[part 1 of 2: package /SwComponentType]
AUTOSAR XML (schema 4-2-2)
package /SwComponentType
  composition sw component type TopLevelComposition
    8 x port group, all with category=PARTIAL_NETWORKING:
      Diagnostics: inner-group=SRS3.Diagnostics
      VehicleDriving: inner-group=SRS3.VehicleDriving
      VehicleModeManagement: inner-group=SRS3.VehicleModeManagement
      SettingsVehicle: inner-group=SRS3.SettingsVehicle
      GlobalShortDuration: inner-group=SRS3.GlobalShortDuration
      Crash: inner-group=SRS3.Crash
      ParkingDrivingClimatization: inner-group=SRS3.ParkingDrivingClimatization
      SeatComfortFunctions: inner-group=SRS3.SeatComfortFunctions
    component SRS3: type=SRS3
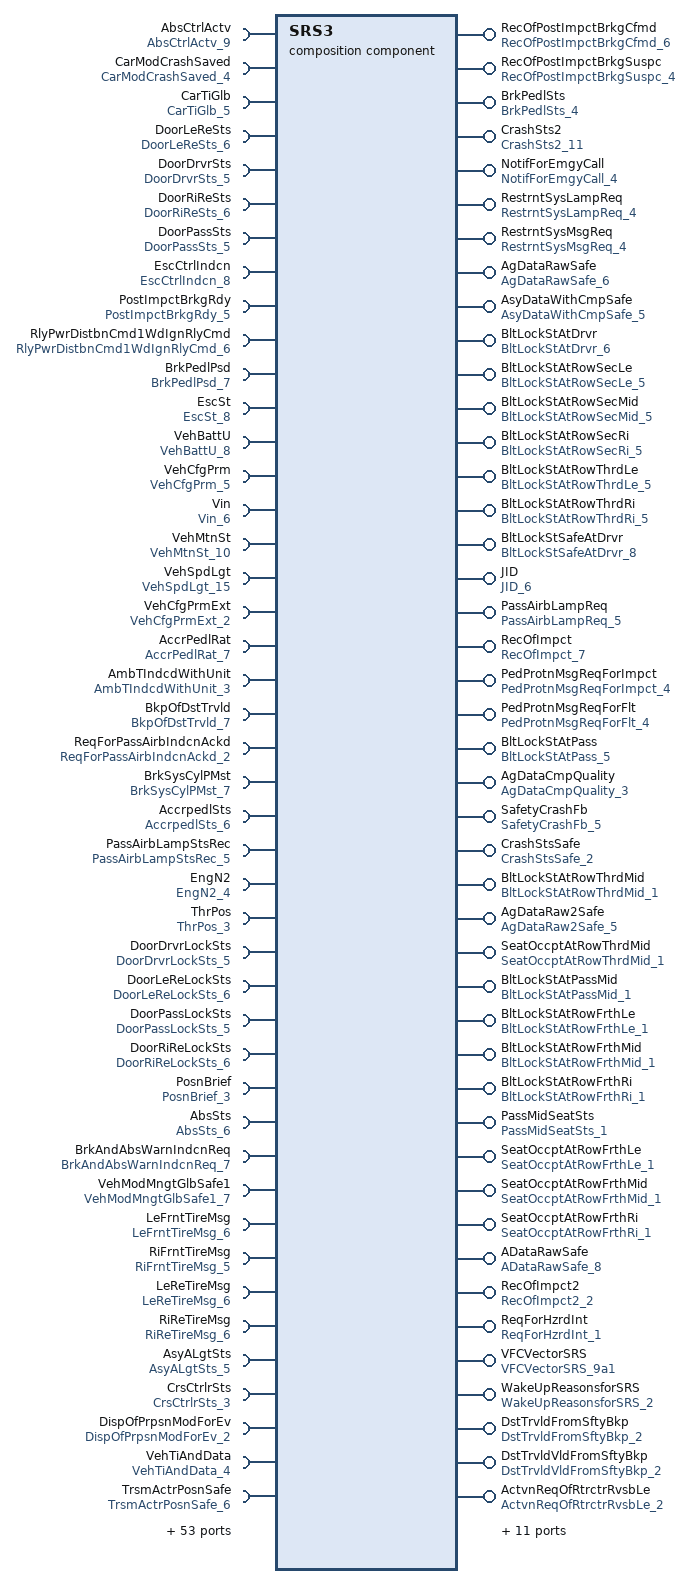
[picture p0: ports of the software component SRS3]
  composition sw component type SRS3
    55 x provide port:
      RecOfPostImpctBrkgCfmd: nonqueued-sender-com-spec{composite-network-representations=[{leaf-element=RecOfPostImpctBrkgCfmd.PostImpctBrkgCfmd, network-representation={base-type=PostImpctBrkgNoYes_2, compu-method=PostImpctBrkgNoYes_1, "ASIL-B(D) signal to inform that a crash has occurred."}}, {leaf-element=RecOfPostImpctBrkgCfmd.CrashFrnt, network-representation={base-type=PostImpctBrkgNoYes_2, compu-method=PostImpctBrkgNoYes_1, "Crash type = front."}}, {leaf-element=RecOfPostImpctBrkgCfmd.CrashSideLe, network-representation={base-type=PostImpctBrkgNoYes_2, compu-method=PostImpctBrkgNoYes_1, "Crash type = left side."}}, {leaf-element=RecOfPostImpctBrkgCfmd.CrashSideRi, network-representation={base-type=PostImpctBrkgNoYes_2, compu-method=PostImpctBrkgNoYes_1, "Crash type = right side."}}, {leaf-element=RecOfPostImpctBrkgCfmd.CrashRe, network-representation={base-type=PostImpctBrkgNoYes_2, compu-method=PostImpctBrkgNoYes_1, "Crash type = rear"}}, {leaf-element=RecOfPostImpctBrkgCfmd.CrashRollovr, network-representation={base-type=PostImpctBrkgNoYes_2, compu-method=PostImpctBrkgNoYes_1, "Crash type = rollover"}}, {leaf-element=RecOfPostImpctBrkgCfmd.CrashPed, network-representation={base-type=PostImpctBrkgNoYes_2, compu-method=PostImpctBrkgNoYes_1, "Crash type = pedestrian impact"}}, {leaf-element=RecOfPostImpctBrkgCfmd.CrashOz, network-representation={base-type=PostImpctBrkgNoYes_2, compu-method=PostImpctBrkgNoYes_1, "Crash type = side offzone (i.e. behind C-pillar or in front of A-pillar.)"}}, {leaf-element=RecOfPostImpctBrkgCfmd.CrashOffroadD, network-representation={base-type=PostImpctBrkgNoYes_2, compu-method=PostImpctBrkgNoYes_1, "Ditch"}}, {leaf-element=RecOfPostImpctBrkgCfmd.CrashOffroadA, network-representation={base-type=PostImpctBrkgNoYes_2, compu-method=PostImpctBrkgNoYes_1, "Airbourne"}}, {leaf-element=RecOfPostImpctBrkgCfmd.CrashOffroadRT, network-representation={base-type=PostImpctBrkgNoYes_2, compu-method=PostImpctBrkgNoYes_1, "Rough Terrain"}}, {leaf-element=RecOfPostImpctBrkgCfmd.CrashOffroadRTsevere, network-representation={base-type=PostImpctBrkgNoYes_2, compu-method=PostImpctBrkgNoYes_1, "Rough Terrain, severe"}}, {leaf-element=RecOfPostImpctBrkgCfmd.CrashLargeAnimal, network-representation={base-type=PostImpctBrkgNoYes_2, compu-method=PostImpctBrkgNoYes_1, "Large Animal"}}, {leaf-element=RecOfPostImpctBrkgCfmd.Chks, network-representation={base-type=UInt8_2, compu {identical; unit Unitless}, "E2E checksum"}}, {leaf-element=RecOfPostImpctBrkgCfmd.Cntr, network-representation={base-type=UInt4_2, compu {identical; unit Unitless}, "E2E counter"}}], data-element=RecOfPostImpctBrkgCfmd, uses-end-to-end-protection=true, init-value=constant-reference=RecOfPostImpctBrkgCfmd_6}, provided-interface=RecOfPostImpctBrkgCfmd_6
      RecOfPostImpctBrkgSuspc: nonqueued-sender-com-spec{composite-network-representations=[{leaf-element=RecOfPostImpctBrkgSuspc.SuspcPostImpctBrkg, network-representation={base-type=PostImpctBrkgNoYes_2, compu-method=PostImpctBrkgNoYes_1, "ASIL-B(D) signal to inform that a crash has occurred."}}, {leaf-element=RecOfPostImpctBrkgSuspc.Chks, network-representation={base-type=UInt8_2, compu {identical; unit Unitless}, "Signal checksum"}}, {leaf-element=RecOfPostImpctBrkgSuspc.Cntr, network-representation={base-type=UInt4_2, compu {identical; unit Unitless}, "Signal counter"}}], data-element=RecOfPostImpctBrkgSuspc, uses-end-to-end-protection=true, init-value=constant-reference=RecOfPostImpctBrkgSuspc_4}, provided-interface=RecOfPostImpctBrkgSuspc_4
      BrkPedlSts: nonqueued-sender-com-spec{data-element=BrkPedlSts, network-representation={base-type=OkNotOk1_2, compu {0=OkNotOk1_Ok, 1=OkNotOk1_NotOk; unit Unitless}, "If the brake pedal decoupling has been activated."}, init-value=constant-reference=BrkPedlSts_4}, provided-interface=BrkPedlSts_4
      CrashSts2: nonqueued-sender-com-spec{data-element=CrashSts2, network-representation={base-type=CrashSts4_1, compu-method=CrashSts4_1, "Information if a crash or slight crash has been detected by SRS."}, init-value=constant-reference=CrashSts2_11}, provided-interface=CrashSts2_11
      NotifForEmgyCall: nonqueued-sender-com-spec{data-element=NotifForEmgyCall, network-representation={base-type=Boolean_2, compu {0=Boolean_FALSE, 1=Boolean_TRUE; unit Unitless}, "Information if there is a need for the vehicle to perform an emergency call."}, init-value=constant-reference=NotifForEmgyCall_4}, provided-interface=NotifForEmgyCall_4
      RestrntSysLampReq: nonqueued-sender-com-spec{data-element=RestrntSysLampReq, network-representation={base-type=RestrntSysLampReq_2, compu-method=RestrntSysLampReq_1, "Indication request for SRS faults."}, init-value=constant-reference=RestrntSysLampReq_4}, provided-interface=RestrntSysLampReq_4
      RestrntSysMsgReq: nonqueued-sender-com-spec{data-element=RestrntSysMsgReq, network-representation={base-type=OnOffCrit1_2, compu-method=OnOffCrit1_1, "Text message request for SRS faults."}, init-value=constant-reference=RestrntSysMsgReq_4}, provided-interface=RestrntSysMsgReq_4
      AgDataRawSafe: nonqueued-sender-com-spec{composite-network-representations=[{leaf-element=AgDataRawSafe.RollRate, network-representation={base-type=AgSpd34_2, compu {phys=raw/4096 for raw -24576..24576; unit rad/s}, "IMU angular rate data. Roll Rate"}}, {leaf-element=AgDataRawSafe.RollRateQf, network-representation={base-type=Qf1_2, compu-method=Qf1_1, "IMU angular rate data. Quality factor for Roll Rate"}}, {leaf-element=AgDataRawSafe.YawRate, network-representation={base-type=AgSpd34_2, compu {phys=raw/4096 for raw -24576..24576; unit rad/s}, "IMU angular rate data. Yaw Rate"}}, {leaf-element=AgDataRawSafe.YawRateQf, network-representation={base-type=Qf1_2, compu-method=Qf1_1, "IMU angular rate data. Quality Factor for Yaw Rate"}}, {leaf-element=AgDataRawSafe.Chks, network-representation={base-type=UInt8_2, compu {identical; unit Unitless}, "IMU angular rate data. Check summa"}}, {leaf-element=AgDataRawSafe.Cntr, network-representation={base-type=UInt4_2, compu {identical; unit Unitless}, "IMU angular rate data. Counter"}}], data-element=AgDataRawSafe, uses-end-to-end-protection=true, init-value=constant-reference=AgDataRawSafe_6}, provided-interface=AgDataRawSafe_6
      AsyDataWithCmpSafe: nonqueued-sender-com-spec{composite-network-representations=[{leaf-element=AsyDataWithCmpSafe.YawRateWithCmp, network-representation={base-type=AgSpd34_2, compu {phys=raw/4096 for raw -24576..24576; unit rad/s}, "IMU processed special data. Compensated Yaw rate"}}, {leaf-element=AsyDataWithCmpSafe.YawRateQf, network-representation={base-type=Qf1_2, compu-method=Qf1_1, "IMU processed special data. Quality Factor for Yaw Rate"}}, {leaf-element=AsyDataWithCmpSafe.ALatWithCmp, network-representation={base-type=A38_2, compu {phys=raw*0.0085 for raw -16352..16353; unit m/s^2}, "IMU processed special data. Compensated Lateral acceleration"}}, {leaf-element=AsyDataWithCmpSafe.ALat1Qf, network-representation={base-type=Qf1_2, compu-method=Qf1_1, "IMU processed special data. Quality factor for Lateral acceleration signal"}}, {leaf-element=AsyDataWithCmpSafe.GrdtOfALgt, network-representation={base-type=Jerk1_2, compu {phys=raw/256 for raw -7680..7680; unit m/s^3}, "IMU processed special data. Derivative of Longitudinal acceleration"}}, {leaf-element=AsyDataWithCmpSafe.ALgt1Qf, network-representation={base-type=Qf1_2, compu-method=Qf1_1, "IMU processed special data. Quality factor for Longitudinal acceleration"}}, {leaf-element=AsyDataWithCmpSafe.Chks, network-representation={base-type=UInt8_2, compu {identical; unit Unitless}, "IMU processed special data. Check sum"}}, {leaf-element=AsyDataWithCmpSafe.Cntr, network-representation={base-type=UInt4_2, compu {identical; unit Unitless}, "IMU processed special data. Counter"}}], data-element=AsyDataWithCmpSafe, uses-end-to-end-protection=true, init-value=constant-reference=AsyDataWithCmpSafe_5}, provided-interface=AsyDataWithCmpSafe_5
      BltLockStAtDrvr: nonqueued-sender-com-spec{composite-network-representations=[{leaf-element=BltLockStAtDrvr.BltLockSt1, network-representation={base-type=BltLockSt1_2, compu {0=BltLockSt1_Unlock, 1=BltLockSt1_Lock; unit Unitless}, "State of belt lock at driver seating position Belt lock state, locked/unlocked"}}, {leaf-element=BltLockStAtDrvr.BltLockSts, network-representation={base-type=DevErrSts2_2, compu {0=DevErrSts2_NoFlt, 1=DevErrSts2_Flt; unit Unitless}, "State of belt lock at driver seating position Belt lock status, OK/NOK"}}], data-element=BltLockStAtDrvr, init-value=constant-reference=BltLockStAtDrvr_6}, provided-interface=BltLockStAtDrvr_6
      BltLockStAtRowSecLe: nonqueued-sender-com-spec{composite-network-representations=[{leaf-element=BltLockStAtRowSecLe.BltLockSt1, network-representation={base-type=BltLockSt1_2, compu {0=BltLockSt1_Unlock, 1=BltLockSt1_Lock; unit Unitless}, "State of belt lock at seating position at left of second row Belt lock state, locked/unlocked"}}, {leaf-element=BltLockStAtRowSecLe.BltLockSts, network-representation={base-type=DevErrSts2_2, compu {0=DevErrSts2_NoFlt, 1=DevErrSts2_Flt; unit Unitless}, "State of belt lock at seating position at left of second row Belt lock status, OK/NOK"}}, {leaf-element=BltLockStAtRowSecLe.BltLockEquid, network-representation={base-type=CptEquid_2, compu {0=CptEquid_Equid, 1=CptEquid_NotEquid; unit Unitless}, "State of belt lock at seating position at left of second row If the belt lock is equipped"}}], data-element=BltLockStAtRowSecLe, init-value=constant-reference=BltLockStAtRowSecLe_5}, provided-interface=BltLockStAtRowSecLe_5
      BltLockStAtRowSecMid: nonqueued-sender-com-spec{composite-network-representations=[{leaf-element=BltLockStAtRowSecMid.BltLockSt1, network-representation={base-type=BltLockSt1_2, compu {0=BltLockSt1_Unlock, 1=BltLockSt1_Lock; unit Unitless}, "State of belt lock at seating position at middle of second row Belt lock state, locked/unlocked"}}, {leaf-element=BltLockStAtRowSecMid.BltLockSts, network-representation={base-type=DevErrSts2_2, compu {0=DevErrSts2_NoFlt, 1=DevErrSts2_Flt; unit Unitless}, "State of belt lock at seating position at middle of second row Belt lock status, OK/NOK"}}, {leaf-element=BltLockStAtRowSecMid.BltLockEquid, network-representation={base-type=CptEquid_2, compu {0=CptEquid_Equid, 1=CptEquid_NotEquid; unit Unitless}, "State of belt lock at seating position at middle of second row If the belt lock is equipped"}}], data-element=BltLockStAtRowSecMid, init-value=constant-reference=BltLockStAtRowSecMid_5}, provided-interface=BltLockStAtRowSecMid_5
      BltLockStAtRowSecRi: nonqueued-sender-com-spec{composite-network-representations=[{leaf-element=BltLockStAtRowSecRi.BltLockSt1, network-representation={base-type=BltLockSt1_2, compu {0=BltLockSt1_Unlock, 1=BltLockSt1_Lock; unit Unitless}, "State of belt lock at seating position at right of second row Belt lock state, locked/unlocked"}}, {leaf-element=BltLockStAtRowSecRi.BltLockSts, network-representation={base-type=DevErrSts2_2, compu {0=DevErrSts2_NoFlt, 1=DevErrSts2_Flt; unit Unitless}, "State of belt lock at seating position at right of second row Belt lock status, OK/NOK"}}, {leaf-element=BltLockStAtRowSecRi.BltLockEquid, network-representation={base-type=CptEquid_2, compu {0=CptEquid_Equid, 1=CptEquid_NotEquid; unit Unitless}, "State of belt lock at seating position at right of second row If the belt lock is equipped"}}], data-element=BltLockStAtRowSecRi, init-value=constant-reference=BltLockStAtRowSecRi_5}, provided-interface=BltLockStAtRowSecRi_5
      BltLockStAtRowThrdLe: nonqueued-sender-com-spec{composite-network-representations=[{leaf-element=BltLockStAtRowThrdLe.BltLockSt1, network-representation={base-type=BltLockSt1_2, compu {0=BltLockSt1_Unlock, 1=BltLockSt1_Lock; unit Unitless}, "State of belt lock at seating position at left of third row Belt lock state, locked/unlocked"}}, {leaf-element=BltLockStAtRowThrdLe.BltLockSts, network-representation={base-type=DevErrSts2_2, compu {0=DevErrSts2_NoFlt, 1=DevErrSts2_Flt; unit Unitless}, "State of belt lock at seating position at left of third row Belt lock status, OK/NOK"}}, {leaf-element=BltLockStAtRowThrdLe.BltLockEquid, network-representation={base-type=CptEquid_2, compu {0=CptEquid_Equid, 1=CptEquid_NotEquid; unit Unitless}, "State of belt lock at seating position at left of third row If the belt lock is equipped"}}], data-element=BltLockStAtRowThrdLe, init-value=constant-reference=BltLockStAtRowThrdLe_5}, provided-interface=BltLockStAtRowThrdLe_5
      BltLockStAtRowThrdRi: nonqueued-sender-com-spec{composite-network-representations=[{leaf-element=BltLockStAtRowThrdRi.BltLockSt1, network-representation={base-type=BltLockSt1_2, compu {0=BltLockSt1_Unlock, 1=BltLockSt1_Lock; unit Unitless}, "State of belt lock at seating position at right of third row Belt lock state, locked/unlocked"}}, {leaf-element=BltLockStAtRowThrdRi.BltLockSts, network-representation={base-type=DevErrSts2_2, compu {0=DevErrSts2_NoFlt, 1=DevErrSts2_Flt; unit Unitless}, "State of belt lock at seating position at right of third row Belt lock status, OK/NOK"}}, {leaf-element=BltLockStAtRowThrdRi.BltLockEquid, network-representation={base-type=CptEquid_2, compu {0=CptEquid_Equid, 1=CptEquid_NotEquid; unit Unitless}, "State of belt lock at seating position at right of third row If the belt lock is equipped"}}], data-element=BltLockStAtRowThrdRi, init-value=constant-reference=BltLockStAtRowThrdRi_5}, provided-interface=BltLockStAtRowThrdRi_5
      BltLockStSafeAtDrvr: nonqueued-sender-com-spec{composite-network-representations=[{leaf-element=BltLockStSafeAtDrvr.BltLockSt1, network-representation={base-type=BltLockSt1_2, compu {0=BltLockSt1_Unlock, 1=BltLockSt1_Lock; unit Unitless}, "State of belt lock at driver seating position Belt lock state, locked/unlocked"}}, {leaf-element=BltLockStSafeAtDrvr.BltLockStErrSts, network-representation={base-type=DevErrSts2_2, compu {0=DevErrSts2_NoFlt, 1=DevErrSts2_Flt; unit Unitless}, "State of belt lock at driver seating position Belt lock status, OK/NOK"}}, {leaf-element=BltLockStSafeAtDrvr.Chks, network-representation={base-type=UInt8_2, compu {identical; unit Unitless}, "Counter for E2E"}}, {leaf-element=BltLockStSafeAtDrvr.Cntr, network-representation={base-type=UInt4_2, compu {identical; unit Unitless}, "Checksum for E2E"}}], data-element=BltLockStSafeAtDrvr, uses-end-to-end-protection=true, init-value=constant-reference=BltLockStSafeAtDrvr_8}, provided-interface=BltLockStSafeAtDrvr_8
      JID: nonqueued-sender-com-spec{composite-network-representations=[{leaf-element=JID.Byte0, network-representation={base-type=UInt8_2, compu {identical; unit Unitless}, "IMU identification number. Byte0"}}, {leaf-element=JID.Byte1, network-representation={base-type=UInt8_2, compu {identical; unit Unitless}, "IMU identification number. Byte1"}}, {leaf-element=JID.Byte2, network-representation={base-type=UInt8_2, compu {identical; unit Unitless}, "IMU identification number. Byte2"}}, {leaf-element=JID.Byte3, network-representation={base-type=UInt8_2, compu {identical; unit Unitless}, "IMU identification number. Byte3"}}, {leaf-element=JID.Byte4, network-representation={base-type=UInt8_2, compu {identical; unit Unitless}, "IMU identification number. Byte4"}}, {leaf-element=JID.Byte5, network-representation={base-type=UInt8_2, compu {identical; unit Unitless}, "IMU identification number. Byte5"}}, {leaf-element=JID.Byte6, network-representation={base-type=UInt8_2, compu {identical; unit Unitless}, "IMU identification number. Byte6"}}, {leaf-element=JID.Byte7, network-representation={base-type=UInt8_2, compu {identical; unit Unitless}, "IMU identification number. Byte7"}}], data-element=JID, init-value=constant-reference=JID_6}, provided-interface=JID_6
      PassAirbLampReq: nonqueued-sender-com-spec{composite-network-representations=[{leaf-element=PassAirbLampReq.PassAirbLampDiReq, network-representation={base-type=PassAirbLampReq_2, compu-method=PassAirbLampReq_1, "Indication request for passenger airbag lamp status. Requested status for PAD lamp"}}, {leaf-element=PassAirbLampReq.PassAirbLampEnaReq, network-representation={base-type=PassAirbLampReq_2, compu-method=PassAirbLampReq_1, "Indication request for passenger airbag lamp status. Requested status for PAE Lamp"}}, {leaf-element=PassAirbLampReq.PassAirbLampReqChks, network-representation={base-type=UInt8_2, compu {identical; unit Unitless}, "Indication request for passenger airbag lamp status. Checksum for validity check of PAD and PAE request messages"}}, {leaf-element=PassAirbLampReq.PassAirbLampReqCntr, network-representation={base-type=UInt4_2, compu {identical; unit Unitless}, "Indication request for passenger airbag lamp status. Counter for validity check of PAD and PAE request messages"}}, {leaf-element=PassAirbLampReq.ChgOfPassAirbSts, network-representation={base-type=ReqForDisp_2, compu {0=ReqForDisp_Idle, 1=ReqForDisp_IndcnReqd; unit Unitless}, "Indication request for passenger airbag lamp status. Reqest for indication of passenger airbag status in DIM"}}], data-element=PassAirbLampReq, uses-end-to-end-protection=true, init-value=constant-reference=PassAirbLampReq_5}, provided-interface=PassAirbLampReq_5
      RecOfImpct: nonqueued-sender-com-spec{composite-network-representations=[{leaf-element=RecOfImpct.VehOri, network-representation={base-type=Orntn_2, compu-method=Orntn_1, "Crash information, Vehicle orientation once crash subsides"}}, {leaf-element=RecOfImpct.CrashState, network-representation={base-type=CrashSt_2, compu-method=CrashSt_1, "Crash information, State of the crash"}}, {leaf-element=RecOfImpct.CrashFrnt, network-representation={base-type=Boolean_2, compu {0=Boolean_FALSE, 1=Boolean_TRUE; unit Unitless}, "Crash information, if crash is frontal"}}, {leaf-element=RecOfImpct.CrashSideLe, network-representation={base-type=Boolean_2, compu {0=Boolean_FALSE, 1=Boolean_TRUE; unit Unitless}, "Crash information, if crash is left side"}}, {leaf-element=RecOfImpct.CrashSideRi, network-representation={base-type=Boolean_2, compu {0=Boolean_FALSE, 1=Boolean_TRUE; unit Unitless}, "Crash information, if crash is right side"}}, {leaf-element=RecOfImpct.CrashRe, network-representation={base-type=Boolean_2, compu {0=Boolean_FALSE, 1=Boolean_TRUE; unit Unitless}, "Crash information, if crash is rear"}}, {leaf-element=RecOfImpct.CrashRollovr, network-representation={base-type=Boolean_2, compu {0=Boolean_FALSE, 1=Boolean_TRUE; unit Unitless}, "Crash information, if crash is roll-over"}}, {leaf-element=RecOfImpct.CrashPed, network-representation={base-type=Boolean_2, compu {0=Boolean_FALSE, 1=Boolean_TRUE; unit Unitless}, "Incident information, if a pedestrian protection triggering has been made"}}, {leaf-element=RecOfImpct.CrashOffroadD, network-representation={base-type=Boolean_2, compu {0=Boolean_FALSE, 1=Boolean_TRUE; unit Unitless}, "Inicdent information, if driving into a ditch has been detected"}}, {leaf-element=RecOfImpct.CrashOffroadA, network-representation={base-type=Boolean_2, compu {0=Boolean_FALSE, 1=Boolean_TRUE; unit Unitless}, "Incident information, if driving off road and becoming airbourne has been detected."}}, {leaf-element=RecOfImpct.CrashOffroadRT, network-representation={base-type=Boolean_2, compu {0=Boolean_FALSE, 1=Boolean_TRUE; unit Unitless}, "Incident information, if driving off the road and into rough terrain has been detected."}}, {leaf-element=RecOfImpct.CrashOffroadRTsevere, network-representation={base-type=Boolean_2, compu {0=Boolean_FALSE, 1=Boolean_TRUE; unit Unitless}, "Incident information, if driving off road and into severe rough terrain has been detected."}}, {leaf-element=RecOfImpct.ImpctDvy, network-representation={base-type=U8Kmph_1, compu {identical; unit Km/h}, "Crash information, change in velocity in y-direction"}}, {leaf-element=RecOfImpct.ImpctDvx, network-representation={base-type=U8Kmph_1, compu {identical; unit Km/h}, "Crash information, change in velocity in x-direction"}}, {leaf-element=RecOfImpct.ImpctRollAg, network-representation={base-type=U8WithRngDeg_1, compu {phys=raw*15 for raw 0..127; unit Deg}, "Crash information, cumulative roll angle"}}], data-element=RecOfImpct, init-value=constant-reference=RecOfImpct_7}, provided-interface=RecOfImpct_7
      PedProtnMsgReqForImpct: nonqueued-sender-com-spec{data-element=PedProtnMsgReqForImpct, network-representation={base-type=OnOff1_2, compu {0=OnOff1_Off, 1=OnOff1_On; unit Unitless}, "Text message request to inform about triggering of the pedestrian protection system."}, init-value=constant-reference=PedProtnMsgReqForImpct_4}, provided-interface=PedProtnMsgReqForImpct_4
      PedProtnMsgReqForFlt: nonqueued-sender-com-spec{data-element=PedProtnMsgReqForFlt, network-representation={base-type=OnOffCrit1_2, compu-method=OnOffCrit1_1, "Indication request for pedestrian protection faults."}, init-value=constant-reference=PedProtnMsgReqForFlt_4}, provided-interface=PedProtnMsgReqForFlt_4
      BltLockStAtPass: nonqueued-sender-com-spec{composite-network-representations=[{leaf-element=BltLockStAtPass.BltLockSt1, network-representation={base-type=BltLockSt1_2, compu {0=BltLockSt1_Unlock, 1=BltLockSt1_Lock; unit Unitless}, "State of belt lock at passenger seating position Belt lock state, locked/unlocked"}}, {leaf-element=BltLockStAtPass.BltLockSts, network-representation={base-type=DevErrSts2_2, compu {0=DevErrSts2_NoFlt, 1=DevErrSts2_Flt; unit Unitless}, "State of belt lock at passenger seating position Belt lock status, OK/NOK"}}], data-element=BltLockStAtPass, init-value=constant-reference=BltLockStAtPass_5}, provided-interface=BltLockStAtPass_5
      AgDataCmpQuality: nonqueued-sender-com-spec{composite-network-representations=[{leaf-element=AgDataCmpQuality.YawRateCmpQuality, network-representation={base-type=UInt8_2, compu {identical; unit Unitless}, "Quality of offset compensation for yawrate"}}, {leaf-element=AgDataCmpQuality.RollRateCmpQuality, network-representation={base-type=UInt8_2, compu {identical; unit Unitless}, "Quality of offset compensation for rollrate"}}, {leaf-element=AgDataCmpQuality.PitchRateCmpQuality, network-representation={base-type=UInt8_2, compu {identical; unit Unitless}, "Quality of offset compensation for pitchrate"}}], data-element=AgDataCmpQuality, init-value=constant-reference=AgDataCmpQuality_3}, provided-interface=AgDataCmpQuality_3
      SafetyCrashFb: nonqueued-sender-com-spec{data-element=SafetyCrashFb, network-representation={base-type=CrashFb_2, compu-method=CrashFb_1, "If brake pedal has been disconnected after a crash it is NOK, else OK after crash."}, init-value=constant-reference=SafetyCrashFb_5}, provided-interface=SafetyCrashFb_5
      CrashStsSafe: nonqueued-sender-com-spec{composite-network-representations=[{leaf-element=CrashStsSafe.Sts, network-representation={base-type=CrashSts2_2, compu {0=CrashSts2_NoCrash, 1=CrashSts2_Crash; unit Unitless}, "Information if a crash has been detected by SRS."}}, {leaf-element=CrashStsSafe.Chks, network-representation={base-type=UInt8_2, compu {identical; unit Unitless}, "Checksum for E2E"}}, {leaf-element=CrashStsSafe.Cntr, network-representation={base-type=UInt4_2, compu {identical; unit Unitless}, "Counter for E2E"}}], data-element=CrashStsSafe, uses-end-to-end-protection=true, init-value=constant-reference=CrashStsSafe_2}, provided-interface=CrashStsSafe_2
      BltLockStAtRowThrdMid: nonqueued-sender-com-spec{composite-network-representations=[{leaf-element=BltLockStAtRowThrdMid.BltLockSt1, network-representation={base-type=BltLockSt1_2, compu {0=BltLockSt1_Unlock, 1=BltLockSt1_Lock; unit Unitless}, "State of belt lock at seating position at middle third row Belt lock state, locked/unlocked"}}, {leaf-element=BltLockStAtRowThrdMid.BltLockSts, network-representation={base-type=DevErrSts2_2, compu {0=DevErrSts2_NoFlt, 1=DevErrSts2_Flt; unit Unitless}, "State of belt lock at seating position at middle third row Belt lock status, OK/NOK"}}, {leaf-element=BltLockStAtRowThrdMid.BltLockEquid, network-representation={base-type=CptEquid_2, compu {0=CptEquid_Equid, 1=CptEquid_NotEquid; unit Unitless}, "State of belt lock at seating position at middle third row If the belt lock is equipped"}}], data-element=BltLockStAtRowThrdMid, init-value=constant-reference=BltLockStAtRowThrdMid_1}, provided-interface=BltLockStAtRowThrdMid_1
      AgDataRaw2Safe: nonqueued-sender-com-spec{composite-network-representations=[{leaf-element=AgDataRaw2Safe.Chks, network-representation={base-type=UInt8_2, compu {identical; unit Unitless}, "IMU pitch rate data. Check sum"}}, {leaf-element=AgDataRaw2Safe.Cntr, network-representation={base-type=UInt4_2, compu {identical; unit Unitless}, "IMU pitch rate data. Counter"}}, {leaf-element=AgDataRaw2Safe.PitchRateQf, network-representation={base-type=Qf1_2, compu-method=Qf1_1, "IMU pitch rate data. Quality factor for Pitch Rate"}}, {leaf-element=AgDataRaw2Safe.PitchRate, network-representation={base-type=AgSpd34_2, compu {phys=raw/4096 for raw -24576..24576; unit rad/s}, "IMU pitch rate data. Pitch Rate"}}], data-element=AgDataRaw2Safe, uses-end-to-end-protection=true, init-value=constant-reference=AgDataRaw2Safe_5}, provided-interface=AgDataRaw2Safe_5
      SeatOccptAtRowThrdMid: nonqueued-sender-com-spec{data-element=SeatOccptAtRowThrdMid, network-representation={base-type=PassSeatSts1_2, compu-method=PassSeatSts1_1, "Occupant presence status at 3rd row , right position."}, init-value=constant-reference=SeatOccptAtRowThrdMid_1}, provided-interface=SeatOccptAtRowThrdMid_1
      BltLockStAtPassMid: nonqueued-sender-com-spec{composite-network-representations=[{leaf-element=BltLockStAtPassMid.BltLockSt1, network-representation={base-type=BltLockSt1_2, compu {0=BltLockSt1_Unlock, 1=BltLockSt1_Lock; unit Unitless}, "Belt lock state at 1st row middle passenger seat position. Signal gives out if the belt lock is locked or unlocked."}}, {leaf-element=BltLockStAtPassMid.BltLockSts, network-representation={base-type=DevErrSts2_2, compu {0=DevErrSts2_NoFlt, 1=DevErrSts2_Flt; unit Unitless}, "Belt lock state at 1st row middle passenger seat position. Signal gives out if the belt lock is faulty or not."}}, {leaf-element=BltLockStAtPassMid.BltLockEquid, network-representation={base-type=CptEquid_2, compu {0=CptEquid_Equid, 1=CptEquid_NotEquid; unit Unitless}, "Belt lock state at 1st row middle passenger seat position. Signal gives out if the belt lock sensor is equipped or not."}}], data-element=BltLockStAtPassMid, init-value=constant-reference=BltLockStAtPassMid_1}, provided-interface=BltLockStAtPassMid_1
      BltLockStAtRowFrthLe: nonqueued-sender-com-spec{composite-network-representations=[{leaf-element=BltLockStAtRowFrthLe.BltLockSt1, network-representation={base-type=BltLockSt1_2, compu {0=BltLockSt1_Unlock, 1=BltLockSt1_Lock; unit Unitless}, "Belt lock state at 4th row outer left seat posiiton. Signal gives out if the belt lock is locked or unlocked."}}, {leaf-element=BltLockStAtRowFrthLe.BltLockSts, network-representation={base-type=DevErrSts2_2, compu {0=DevErrSts2_NoFlt, 1=DevErrSts2_Flt; unit Unitless}, "Belt lock fault status at the 4th row outer left seat. Signal gives out if belt lock is faulty or not."}}, {leaf-element=BltLockStAtRowFrthLe.BltLockEquid, network-representation={base-type=CptEquid_2, compu {0=CptEquid_Equid, 1=CptEquid_NotEquid; unit Unitless}, "Signal gives out if belt lock detection sensor is equipped at the 4th row outer left seat."}}], data-element=BltLockStAtRowFrthLe, init-value=constant-reference=BltLockStAtRowFrthLe_1}, provided-interface=BltLockStAtRowFrthLe_1
      BltLockStAtRowFrthMid: nonqueued-sender-com-spec{composite-network-representations=[{leaf-element=BltLockStAtRowFrthMid.BltLockSt1, network-representation={base-type=BltLockSt1_2, compu {0=BltLockSt1_Unlock, 1=BltLockSt1_Lock; unit Unitless}, "Belt lock state at 4th row middle seat posiiton. Signal gives out if the belt lock is locked or unlocked."}}, {leaf-element=BltLockStAtRowFrthMid.BltLockSts, network-representation={base-type=DevErrSts2_2, compu {0=DevErrSts2_NoFlt, 1=DevErrSts2_Flt; unit Unitless}, "Belt lock fault status at the 4th row middle seat. Signal gives out if belt lock is faulty or not."}}, {leaf-element=BltLockStAtRowFrthMid.BltLockEquid, network-representation={base-type=CptEquid_2, compu {0=CptEquid_Equid, 1=CptEquid_NotEquid; unit Unitless}, "Signal gives out if belt lock detection sensor is equipped at the 4th row middle seat."}}], data-element=BltLockStAtRowFrthMid, init-value=constant-reference=BltLockStAtRowFrthMid_1}, provided-interface=BltLockStAtRowFrthMid_1
      BltLockStAtRowFrthRi: nonqueued-sender-com-spec{composite-network-representations=[{leaf-element=BltLockStAtRowFrthRi.BltLockSt1, network-representation={base-type=BltLockSt1_2, compu {0=BltLockSt1_Unlock, 1=BltLockSt1_Lock; unit Unitless}, "Belt lock state at 4th row outer right seat posiiton. Signal gives out if the belt lock is locked or unlocked."}}, {leaf-element=BltLockStAtRowFrthRi.BltLockSts, network-representation={base-type=DevErrSts2_2, compu {0=DevErrSts2_NoFlt, 1=DevErrSts2_Flt; unit Unitless}, "Belt lock fault status at the 4th row outer right seat. Signal gives out if belt lock is faulty or not."}}, {leaf-element=BltLockStAtRowFrthRi.BltLockEquid, network-representation={base-type=CptEquid_2, compu {0=CptEquid_Equid, 1=CptEquid_NotEquid; unit Unitless}, "Signal gives out if belt lock detection sensor is equipped at the 4th row outer right seat."}}], data-element=BltLockStAtRowFrthRi, init-value=constant-reference=BltLockStAtRowFrthRi_1}, provided-interface=BltLockStAtRowFrthRi_1
      PassMidSeatSts: nonqueued-sender-com-spec{data-element=PassMidSeatSts, network-representation={base-type=PassSeatSts1_2, compu-method=PassSeatSts1_1, "Occupation status based on occupant detection sensor at front row middle seat."}, init-value=constant-reference=PassMidSeatSts_1}, provided-interface=PassMidSeatSts_1
      SeatOccptAtRowFrthLe: nonqueued-sender-com-spec{data-element=SeatOccptAtRowFrthLe, network-representation={base-type=PassSeatSts1_2, compu-method=PassSeatSts1_1, "Occupation status based on occupant detection sensor at the 4th row outer left seat."}, init-value=constant-reference=SeatOccptAtRowFrthLe_1}, provided-interface=SeatOccptAtRowFrthLe_1
      SeatOccptAtRowFrthMid: nonqueued-sender-com-spec{data-element=SeatOccptAtRowFrthMid, network-representation={base-type=PassSeatSts1_2, compu-method=PassSeatSts1_1, "Occupation status based on occupant detection sensor at the 4th middle seat."}, init-value=constant-reference=SeatOccptAtRowFrthMid_1}, provided-interface=SeatOccptAtRowFrthMid_1
      SeatOccptAtRowFrthRi: nonqueued-sender-com-spec{data-element=SeatOccptAtRowFrthRi, network-representation={base-type=PassSeatSts1_2, compu-method=PassSeatSts1_1, "Occupation status based on occupant detection sensor at the 4th row outer right seat."}, init-value=constant-reference=SeatOccptAtRowFrthRi_1}, provided-interface=SeatOccptAtRowFrthRi_1
      ADataRawSafe: nonqueued-sender-com-spec{composite-network-representations=[{leaf-element=ADataRawSafe.ALat, network-representation={base-type=A38_2, compu {phys=raw*0.0085 for raw -16352..16353; unit m/s^2}, "IMU acceleration data Lateral acceleration"}}, {leaf-element=ADataRawSafe.ALat1Qf, network-representation={base-type=Qf1_2, compu-method=Qf1_1, "IMU acceleration data Quality factor for Lateral acceleration signal"}}, {leaf-element=ADataRawSafe.ALgt, network-representation={base-type=A38_2, compu {phys=raw*0.0085 for raw -16352..16353; unit m/s^2}, "IMU acceleration data Longitudinal acceleration"}}, {leaf-element=ADataRawSafe.ALgt1Qf, network-representation={base-type=Qf1_2, compu-method=Qf1_1, "IMU acceleration data Quality factor for Longitudinal acceleration"}}, {leaf-element=ADataRawSafe.AVert, network-representation={base-type=A38_2, compu {phys=raw*0.0085 for raw -16352..16353; unit m/s^2}, "IMU acceleration data Vertical acceleration"}}, {leaf-element=ADataRawSafe.AVertQf, network-representation={base-type=Qf1_2, compu-method=Qf1_1, "IMU acceleration data Quality factor for Vertical acceleration"}}, {leaf-element=ADataRawSafe.Chks, network-representation={base-type=UInt8_2, compu {identical; unit Unitless}, "IMU acceleration data Check sum"}}, {leaf-element=ADataRawSafe.Cntr, network-representation={base-type=UInt4_2, compu {identical; unit Unitless}, "IMU acceleration data Counter"}}], data-element=ADataRawSafe, uses-end-to-end-protection=true, init-value=constant-reference=ADataRawSafe_8}, provided-interface=ADataRawSafe_8
      RecOfImpct2: nonqueued-sender-com-spec{composite-network-representations=[{leaf-element=RecOfImpct2.ImpctDvxSigned, network-representation={base-type=Spd51_1, compu {phys=raw-255 for raw 0..512; unit Km/h}, "Crash information , changed velocity in x direction , data with sign"}}, {leaf-element=RecOfImpct2.ImpctDvySigned, network-representation={base-type=Spd51_1, compu {phys=raw-255 for raw 0..512; unit Km/h}, "Crash information , changed velocity in y direction, data with sign"}}], data-element=RecOfImpct2, init-value=constant-reference=RecOfImpct2_2}, provided-interface=RecOfImpct2_2
      ReqForHzrdInt: nonqueued-sender-com-spec{data-element=ReqForHzrdInt, network-representation={base-type=ReqForHzrdInt_1, compu-method=ReqForHzrdInt_1, "0-Lower crash not happen 1-Lower crash happened"}, init-value=constant-reference=ReqForHzrdInt_1}, provided-interface=ReqForHzrdInt_1
      VFCVectorSRS: nonqueued-sender-com-spec{composite-network-representations=[{leaf-element=VFCVectorSRS.VFCid1, network-representation={base-type=VFCOnOff_4, compu {0=VFCOnOff_Off, 1=VFCOnOff_On; unit Unitless}, "ParkingDrivingClimatization"}}, {leaf-element=VFCVectorSRS.VFCid2, network-representation={base-type=VFCOnOff_4, compu {0=VFCOnOff_Off, 1=VFCOnOff_On; unit Unitless}, "PostClimatisation"}}, {leaf-element=VFCVectorSRS.VFCid3, network-representation={base-type=VFCOnOff_4, compu {0=VFCOnOff_Off, 1=VFCOnOff_On; unit Unitless}, "PowertrainParkingClimatization"}}, {leaf-element=VFCVectorSRS.VFCid4, network-representation={base-type=VFCOnOff_4, compu {0=VFCOnOff_Off, 1=VFCOnOff_On; unit Unitless}, "VFC4"}}, {leaf-element=VFCVectorSRS.VFCid5, network-representation={base-type=VFCOnOff_4, compu {0=VFCOnOff_Off, 1=VFCOnOff_On; unit Unitless}, "VFC5"}}, {leaf-element=VFCVectorSRS.VFCid6, network-representation={base-type=VFCOnOff_4, compu {0=VFCOnOff_Off, 1=VFCOnOff_On; unit Unitless}, "SettingsVehicle"}}, {leaf-element=VFCVectorSRS.VFCid7, network-representation={base-type=VFCOnOff_4, compu {0=VFCOnOff_Off, 1=VFCOnOff_On; unit Unitless}, "VFC7"}}, {leaf-element=VFCVectorSRS.VFCid8, network-representation={base-type=VFCOnOff_4, compu {0=VFCOnOff_Off, 1=VFCOnOff_On; unit Unitless}, "VFC8"}}, {leaf-element=VFCVectorSRS.VFCid9, network-representation={base-type=VFCOnOff_4, compu {0=VFCOnOff_Off, 1=VFCOnOff_On; unit Unitless}, "IPWakeup"}}, {leaf-element=VFCVectorSRS.VFCid10, network-representation={base-type=VFCOnOff_4, compu {0=VFCOnOff_Off, 1=VFCOnOff_On; unit Unitless}, "ExteriorLighting"}}, {leaf-element=VFCVectorSRS.VFCid11, network-representation={base-type=VFCOnOff_4, compu {0=VFCOnOff_Off, 1=VFCOnOff_On; unit Unitless}, "VFC11"}}, {leaf-element=VFCVectorSRS.VFCid12, network-representation={base-type=VFCOnOff_4, compu {0=VFCOnOff_Off, 1=VFCOnOff_On; unit Unitless}, "Alarm"}}, {leaf-element=VFCVectorSRS.VFCid13, network-representation={base-type=VFCOnOff_4, compu {0=VFCOnOff_Off, 1=VFCOnOff_On; unit Unitless}, "VFC13"}}, {leaf-element=VFCVectorSRS.VFCid14, network-representation={base-type=VFCOnOff_4, compu {0=VFCOnOff_Off, 1=VFCOnOff_On; unit Unitless}, "InteriorLighting"}}, {leaf-element=VFCVectorSRS.VFCid15, network-representation={base-type=VFCOnOff_4, compu {0=VFCOnOff_Off, 1=VFCOnOff_On; unit Unitless}, "VFC15"}}, {leaf-element=VFCVectorSRS.VFCid16, network-representation={base-type=VFCOnOff_4, compu {0=VFCOnOff_Off, 1=VFCOnOff_On; unit Unitless}, "Locking"}}, {leaf-element=VFCVectorSRS.VFCid17, network-representation={base-type=VFCOnOff_4, compu {0=VFCOnOff_Off, 1=VFCOnOff_On; unit Unitless}, "RemoteKeyFunctionality"}}, {leaf-element=VFCVectorSRS.VFCid18, network-representation={base-type=VFCOnOff_4, compu {0=VFCOnOff_Off, 1=VFCOnOff_On; unit Unitless}, "PropulsionStart"}}, {leaf-element=VFCVectorSRS.VFCid19, network-representation={base-type=VFCOnOff_4, compu {0=VFCOnOff_Off, 1=VFCOnOff_On; unit Unitless}, "VFC19"}}, {leaf-element=VFCVectorSRS.VFCid20, network-representation={base-type=VFCOnOff_4, compu {0=VFCOnOff_Off, 1=VFCOnOff_On; unit Unitless}, "VFC20"}}, {leaf-element=VFCVectorSRS.VFCid21, network-representation={base-type=VFCOnOff_4, compu {0=VFCOnOff_Off, 1=VFCOnOff_On; unit Unitless}, "PowerClosures"}}, {leaf-element=VFCVectorSRS.VFCid22, network-representation={base-type=VFCOnOff_4, compu {0=VFCOnOff_Off, 1=VFCOnOff_On; unit Unitless}, "VehicleDriving"}}, {leaf-element=VFCVectorSRS.VFCid23, network-representation={base-type=VFCOnOff_4, compu {0=VFCOnOff_Off, 1=VFCOnOff_On; unit Unitless}, "VFC23"}}, {leaf-element=VFCVectorSRS.VFCid24, network-representation={base-type=VFCOnOff_4, compu {0=VFCOnOff_Off, 1=VFCOnOff_On; unit Unitless}, "SettingsProfile"}}, {leaf-element=VFCVectorSRS.VFCid25, network-representation={base-type=VFCOnOff_4, compu {0=VFCOnOff_Off, 1=VFCOnOff_On; unit Unitless}, "SeatComfortFunctions"}}, {leaf-element=VFCVectorSRS.VFCid26, network-representation={base-type=VFCOnOff_4, compu {0=VFCOnOff_Off, 1=VFCOnOff_On; unit Unitless}, "Brake"}}, {leaf-element=VFCVectorSRS.VFCid27, network-representation={base-type=VFCOnOff_4, compu {0=VFCOnOff_Off, 1=VFCOnOff_On; unit Unitless}, "InfotainmentPoll"}}, {leaf-element=VFCVectorSRS.VFCid28, network-representation={base-type=VFCOnOff_4, compu {0=VFCOnOff_Off, 1=VFCOnOff_On; unit Unitless}, "HVEnergyStorage"}}, {leaf-element=VFCVectorSRS.VFCid29, network-representation={base-type=VFCOnOff_4, compu {0=VFCOnOff_Off, 1=VFCOnOff_On; unit Unitless}, "VFC29"}}, {leaf-element=VFCVectorSRS.VFCid30, network-representation={base-type=VFCOnOff_4, compu {0=VFCOnOff_Off, 1=VFCOnOff_On; unit Unitless}, "TelematicsConnectivity"}}, {leaf-element=VFCVectorSRS.VFCid31, network-representation={base-type=VFCOnOff_4, compu {0=VFCOnOff_Off, 1=VFCOnOff_On; unit Unitless}, "VFC31"}}, {leaf-element=VFCVectorSRS.VFCid32, network-representation={base-type=VFCOnOff_4, compu {0=VFCOnOff_Off, 1=VFCOnOff_On; unit Unitless}, "VFC32"}}, {leaf-element=VFCVectorSRS.VFCid33, network-representation={base-type=VFCOnOff_4, compu {0=VFCOnOff_Off, 1=VFCOnOff_On; unit Unitless}, "Diagnostics"}}, {leaf-element=VFCVectorSRS.VFCid34, network-representation={base-type=VFCOnOff_4, compu {0=VFCOnOff_Off, 1=VFCOnOff_On; unit Unitless}, "VehicleModeManagement"}}, {leaf-element=VFCVectorSRS.VFCid35, network-representation={base-type=VFCOnOff_4, compu {0=VFCOnOff_Off, 1=VFCOnOff_On; unit Unitless}, "TrailerCaravanFunctions"}}, {leaf-element=VFCVectorSRS.VFCid36, network-representation={base-type=VFCOnOff_4, compu {0=VFCOnOff_Off, 1=VFCOnOff_On; unit Unitless}, "Immobilizer"}}, {leaf-element=VFCVectorSRS.VFCid37, network-representation={base-type=VFCOnOff_4, compu {0=VFCOnOff_Off, 1=VFCOnOff_On; unit Unitless}, "Windows"}}, {leaf-element=VFCVectorSRS.VFCid38, network-representation={base-type=VFCOnOff_4, compu {0=VFCOnOff_Off, 1=VFCOnOff_On; unit Unitless}, "Visibility"}}, {leaf-element=VFCVectorSRS.VFCid39, network-representation={base-type=VFCOnOff_4, compu {0=VFCOnOff_Off, 1=VFCOnOff_On; unit Unitless}, "VFC39"}}, {leaf-element=VFCVectorSRS.VFCid40, network-representation={base-type=VFCOnOff_4, compu {0=VFCOnOff_Off, 1=VFCOnOff_On; unit Unitless}, "VFC40"}}, {leaf-element=VFCVectorSRS.VFCid41, network-representation={base-type=VFCOnOff_4, compu {0=VFCOnOff_Off, 1=VFCOnOff_On; unit Unitless}, "InfotainmentPush"}}, {leaf-element=VFCVectorSRS.VFCid42, network-representation={base-type=VFCOnOff_4, compu {0=VFCOnOff_Off, 1=VFCOnOff_On; unit Unitless}, "ChargingHV"}}, {leaf-element=VFCVectorSRS.VFCid43, network-representation={base-type=VFCOnOff_4, compu {0=VFCOnOff_Off, 1=VFCOnOff_On; unit Unitless}, "BodyPreClimatisation"}}, {leaf-element=VFCVectorSRS.VFCid44, network-representation={base-type=VFCOnOff_4, compu {0=VFCOnOff_Off, 1=VFCOnOff_On; unit Unitless}, "Crash"}}, {leaf-element=VFCVectorSRS.VFCid45, network-representation={base-type=VFCOnOff_4, compu {0=VFCOnOff_Off, 1=VFCOnOff_On; unit Unitless}, "GlobalShortDuration"}}, {leaf-element=VFCVectorSRS.VFCid46, network-representation={base-type=VFCOnOff_4, compu {0=VFCOnOff_Off, 1=VFCOnOff_On; unit Unitless}, "ExteriorLightsHazard"}}, {leaf-element=VFCVectorSRS.VFCid47, network-representation={base-type=VFCOnOff_4, compu {0=VFCOnOff_Off, 1=VFCOnOff_On; unit Unitless}, "VFC47"}}, {leaf-element=VFCVectorSRS.VFCid48, network-representation={base-type=VFCOnOff_4, compu {0=VFCOnOff_Off, 1=VFCOnOff_On; unit Unitless}, "DoorOpenWarning"}}, {leaf-element=VFCVectorSRS.VFCid49, network-representation={base-type=VFCOnOff_4, compu {0=VFCOnOff_Off, 1=VFCOnOff_On; unit Unitless}, "ChargingLVInit"}}, {leaf-element=VFCVectorSRS.VFCid50, network-representation={base-type=VFCOnOff_4, compu {0=VFCOnOff_Off, 1=VFCOnOff_On; unit Unitless}, "VFC50"}}, {leaf-element=VFCVectorSRS.VFCid51, network-representation={base-type=VFCOnOff_4, compu {0=VFCOnOff_Off, 1=VFCOnOff_On; unit Unitless}, "VFC51"}}, {leaf-element=VFCVectorSRS.VFCid52, network-representation={base-type=VFCOnOff_4, compu {0=VFCOnOff_Off, 1=VFCOnOff_On; unit Unitless}, "HVBatteryThermalEventWarning"}}, {leaf-element=VFCVectorSRS.VFCid53, network-representation={base-type=VFCOnOff_4, compu {0=VFCOnOff_Off, 1=VFCOnOff_On; unit Unitless}, "VisualAssist"}}, {leaf-element=VFCVectorSRS.VFCid54, network-representation={base-type=VFCOnOff_4, compu {0=VFCOnOff_Off, 1=VFCOnOff_On; unit Unitless}, "PassiveSafety"}}, {leaf-element=VFCVectorSRS.VFCid55, network-representation={base-type=VFCOnOff_4, compu {0=VFCOnOff_Off, 1=VFCOnOff_On; unit Unitless}, "LifeDetection"}}, {leaf-element=VFCVectorSRS.VFCid56, network-representation={base-type=VFCOnOff_4, compu {0=VFCOnOff_Off, 1=VFCOnOff_On; unit Unitless}, "BackboneFlexray"}}, {leaf-element=VFCVectorSRS.VFCid57, network-representation={base-type=VFCOnOff_4, compu {0=VFCOnOff_Off, 1=VFCOnOff_On; unit Unitless}, "Functionmarket"}}, {leaf-element=VFCVectorSRS.VFCid58, network-representation={base-type=VFCOnOff_4, compu {0=VFCOnOff_Off, 1=VFCOnOff_On; unit Unitless}, "VFC58"}}, {leaf-element=VFCVectorSRS.VFCid59, network-representation={base-type=VFCOnOff_4, compu {0=VFCOnOff_Off, 1=VFCOnOff_On; unit Unitless}, "VFC59"}}, {leaf-element=VFCVectorSRS.VFCid60, network-representation={base-type=VFCOnOff_4, compu {0=VFCOnOff_Off, 1=VFCOnOff_On; unit Unitless}, "VFC60"}}, {leaf-element=VFCVectorSRS.VFCid61, network-representation={base-type=VFCOnOff_4, compu {0=VFCOnOff_Off, 1=VFCOnOff_On; unit Unitless}, "VFC61"}}, {leaf-element=VFCVectorSRS.VFCid0, network-representation={base-type=VFCOnOff_4, compu {0=VFCOnOff_Off, 1=VFCOnOff_On; unit Unitless}, "SettingsComfort"}}, {leaf-element=VFCVectorSRS.BlockID, network-representation={base-type=BlockID_3, compu {identical; unit Unitless}, "BlockID"}}], data-element=VFCVectorSRS, init-value=constant-reference=VFCVectorSRS_9a1}, provided-interface=VFCVectorSRS_9a1
      WakeUpReasonsforSRS: nonqueued-sender-com-spec{data-element=WakeUpReasonsforSRS, network-representation={base-type=WakeUpReasons_4, compu-method=WakeupReasons_7, "WakeUpReasons"}, init-value=constant-reference=WakeUpReasonsforSRS_2}, provided-interface=WakeUpReasonsforSRS_2
      DstTrvldFromSftyBkp: nonqueued-sender-com-spec{data-element=DstTrvldFromSftyBkp, network-representation={base-type=Len31_2, compu {phys=raw for raw 0..2000000; unit km}, "Saved backupvalue"}, init-value=constant-reference=DstTrvldFromSftyBkp_2}, provided-interface=DstTrvldFromSftyBkp_2
      DstTrvldVldFromSftyBkp: nonqueued-sender-com-spec{data-element=DstTrvldVldFromSftyBkp, network-representation={base-type=InvldVld1_2, compu {0=InvldVld1_Invld, 1=InvldVld1_Vld; unit Unitless}, "Indication if the transmitted backupvalue is valid or not"}, init-value=constant-reference=DstTrvldVldFromSftyBkp_2}, provided-interface=DstTrvldVldFromSftyBkp_2
      ActvnReqOfRtrctrRvsbLe: nonqueued-sender-com-spec{data-element=ActvnReqOfRtrctrRvsbLe, network-representation={base-type=ActvnReqOfRtrctrRvsb1_2, compu {0=NoActvn, 1=ActvnFLo, 2=ActvnFHi, 3=Resd1, 4=Resd2; unit Unitless}, "Belt pre-tensioning request from the DART/CWS algo in the SRS."}, init-value=constant-reference=ActvnReqOfRtrctrRvsbLe_2}, provided-interface=ActvnReqOfRtrctrRvsbLe_2
      ActvnReqOfRtrctrRvsbRi: nonqueued-sender-com-spec{data-element=ActvnReqOfRtrctrRvsbRi, network-representation={base-type=ActvnReqOfRtrctrRvsb1_2, compu {0=NoActvn, 1=ActvnFLo, 2=ActvnFHi, 3=Resd1, 4=Resd2; unit Unitless}, "Belt pre-tensioning request from the DART/CWS algo in the SRS."}, init-value=constant-reference=ActvnReqOfRtrctrRvsbRi_2}, provided-interface=ActvnReqOfRtrctrRvsbRi_2
      BltCrashNotif: nonqueued-sender-com-spec{composite-network-representations=[{leaf-element=BltCrashNotif.BltCrashNotifDrvr, network-representation={base-type=NoYesCrit1_2, compu-method=NoYesCrit1_1, "Status signal for driver belt pyrotechnic activation."}}, {leaf-element=BltCrashNotif.BltCrashNotifPass, network-representation={base-type=NoYesCrit1_2, compu-method=NoYesCrit1_1, "Status signal for passenger belt pyrotechnic activation."}}], data-element=BltCrashNotif, init-value=constant-reference=BltCrashNotif_4}, provided-interface=BltCrashNotif_4
      PassAirbSts: nonqueued-sender-com-spec{data-element=PassAirbSts, network-representation={base-type=OnOff2_2, compu {0=OnOff2_On, 1=OnOff2_Off; unit Unitless}, "Passenger airbag status, based on PACOS input."}, init-value=constant-reference=PassAirbSts_5}, provided-interface=PassAirbSts_5
      SRSdevelpsignalgroupTX: nonqueued-sender-com-spec{composite-network-representations=[{leaf-element=SRSdevelpsignalgroupTX.Functiondevpsignalgroup1, network-representation={base-type=UInt8_2, compu {identical; unit Unitless}, "SRS development signal"}}, {leaf-element=SRSdevelpsignalgroupTX.Functiondevpsignalgroup2, network-representation={base-type=UInt8_2, compu {identical; unit Unitless}, "SRS development signal"}}, {leaf-element=SRSdevelpsignalgroupTX.Functiondevpsignalgroup3, network-representation={base-type=UInt8_2, compu {identical; unit Unitless}, "SRS development signal"}}, {leaf-element=SRSdevelpsignalgroupTX.Functiondevpsignalgroup4, network-representation={base-type=UInt8_2, compu {identical; unit Unitless}, "SRS development signal"}}, {leaf-element=SRSdevelpsignalgroupTX.Functiondevpsignalgroup5, network-representation={base-type=UInt8_2, compu {identical; unit Unitless}, "SRS development signal"}}, {leaf-element=SRSdevelpsignalgroupTX.Functiondevpsignalgroup6, network-representation={base-type=UInt8_2, compu {identical; unit Unitless}, "SRS development signal"}}, {leaf-element=SRSdevelpsignalgroupTX.Functiondevpsignalgroup7, network-representation={base-type=UInt8_2, compu {identical; unit Unitless}, "SRS development signal"}}, {leaf-element=SRSdevelpsignalgroupTX.Functiondevpsignalgroup8, network-representation={base-type=UInt8_2, compu {identical; unit Unitless}, "SRS development signal"}}], data-element=SRSdevelpsignalgroupTX, init-value=constant-reference=SRSdevelpsignalgroupTX_3}, provided-interface=SRSdevelpsignalgroupTX_3
      SRSResdSig1ToZCUDMSafety: nonqueued-sender-com-spec{composite-network-representations=[{leaf-element=SRSResdSig1ToZCUDMSafety.Chks, network-representation={base-type=UInt8_2, compu {identical; unit Unitless}, "SRSResdSig1ToZCUDMSafety"}}, {leaf-element=SRSResdSig1ToZCUDMSafety.Cntr, network-representation={base-type=UInt4_2, compu {identical; unit Unitless}, "SRSResdSig1ToZCUDMSafety"}}, {leaf-element=SRSResdSig1ToZCUDMSafety.UInt32, network-representation={base-type=UInt32_2, compu {identical; unit Unitless}, "SRSResdSig1ToZCUDMSafety"}}], data-element=SRSResdSig1ToZCUDMSafety, uses-end-to-end-protection=true, init-value=constant-reference=SRSResdSig1ToZCUDMSafety_1}, provided-interface=SRSResdSig1ToZCUDMSafety_1
      HVfault: nonqueued-sender-com-spec{data-element=HVfault, network-representation={base-type=Boolean_2, compu {0=Boolean_FALSE, 1=Boolean_TRUE; unit Unitless}, "0: No fault 1: There is one fault qualified at least"}, init-value=constant-reference=HVfault_1}, provided-interface=HVfault_1
      SRSIntVolt: nonqueued-sender-com-spec{data-element=SRSIntVolt, network-representation={base-type=U55_1, compu {phys=raw*0.1 for raw 0..255; unit Volt}, "SRS internal voltage"}, init-value=constant-reference=SRSIntVolt_1}, provided-interface=SRSIntVolt_1
      SftyAirbRollovrSuppSts: nonqueued-sender-com-spec{data-element=SftyAirbRollovrSuppSts, network-representation={base-type=OnOff1_2, compu {0=OnOff1_Off, 1=OnOff1_On; unit Unitless}, "Roll-over deactivation actual state"}, init-value=constant-reference=SftyAirbRollovrSuppSts_1}, provided-interface=SftyAirbRollovrSuppSts_1
      ReqForAsyDataStorgFromRestrntSys: nonqueued-sender-com-spec{data-element=ReqForAsyDataStorgFromRestrntSys, network-representation={base-type=Boolean_2, compu {0=Boolean_FALSE, 1=Boolean_TRUE; unit Unitless}, "ASY Data Storg from restrn system"}, init-value=constant-reference=ReqForAsyDataStorgFromRestrntSys_1}, provided-interface=ReqForAsyDataStorgFromRestrntSys_1
      IntgtIMUDataRawSafe: nonqueued-sender-com-spec{composite-network-representations=[{leaf-element=IntgtIMUDataRawSafe.ALat, network-representation={base-type=A38_2, compu {phys=raw*0.0085 for raw -16352..16353; unit m/s^2}, "IMU acceleration data Lateral acceleration"}}, {leaf-element=IntgtIMUDataRawSafe.ALat1Qf, network-representation={base-type=Qf1_2, compu-method=Qf1_1, "QF for Lateral acceleration"}}, {leaf-element=IntgtIMUDataRawSafe.ALgt, network-representation={base-type=A38_2, compu {phys=raw*0.0085 for raw -16352..16353; unit m/s^2}, "IMU acceleration data Longitudinal acceleration"}}, {leaf-element=IntgtIMUDataRawSafe.ALgt1Qf, network-representation={base-type=Qf1_2, compu-method=Qf1_1, "QF for Longitudinal acceleration"}}, {leaf-element=IntgtIMUDataRawSafe.Avert, network-representation={base-type=A38_2, compu {phys=raw*0.0085 for raw -16352..16353; unit m/s^2}, "IMU acceleration data Vertical acceleration"}}, {leaf-element=IntgtIMUDataRawSafe.AVertQf, network-representation={base-type=Qf1_2, compu-method=Qf1_1, "QF for Vertical acceleration"}}, {leaf-element=IntgtIMUDataRawSafe.YawRate, network-representation={base-type=AgSpd34_2, compu {phys=raw/4096 for raw -24576..24576; unit rad/s}, "IMU angular rate Yaw rate"}}, {leaf-element=IntgtIMUDataRawSafe.YawRateQf, network-representation={base-type=Qf1_2, compu-method=Qf1_1, "QF for Yaw rate"}}, {leaf-element=IntgtIMUDataRawSafe.RollRate, network-representation={base-type=AgSpd34_2, compu {phys=raw/4096 for raw -24576..24576; unit rad/s}, "IMU angular rate Roll rate"}}, {leaf-element=IntgtIMUDataRawSafe.RollRateQf, network-representation={base-type=Qf1_2, compu-method=Qf1_1, "QF for Roll rate"}}, {leaf-element=IntgtIMUDataRawSafe.PitchRate, network-representation={base-type=AgSpd34_2, compu {phys=raw/4096 for raw -24576..24576; unit rad/s}, "IMU angular rate Pitch rate"}}, {leaf-element=IntgtIMUDataRawSafe.PitchRateQf, network-representation={base-type=Qf1_2, compu-method=Qf1_1, "QF for Pitch rate"}}, {leaf-element=IntgtIMUDataRawSafe.Chks, network-representation={base-type=UInt8_2, compu {identical; unit Unitless}, "Check summa"}}, {leaf-element=IntgtIMUDataRawSafe.Cntr, network-representation={base-type=UInt4_2, compu {identical; unit Unitless}, "Counter"}}], data-element=IntgtIMUDataRawSafe, uses-end-to-end-protection=true, init-value=constant-reference=IntgtIMUDataRawSafe_1}, provided-interface=IntgtIMUDataRawSafe_1
      PassAirbStsChgNotifReq: nonqueued-sender-com-spec{data-element=PassAirbStsChgNotifReq, network-representation={base-type=ReqForDisp_2, compu {0=ReqForDisp_Idle, 1=ReqForDisp_IndcnReqd; unit Unitless}, "Request for a popup window notification to promot user to change the passenger airbag status."}, init-value=constant-reference=PassAirbStsChgNotifReq_1}, provided-interface=PassAirbStsChgNotifReq_1
    101 x require port:
      AbsCtrlActv: nonqueued-receiver-com-spec{composite-network-representations=[{leaf-element=AbsCtrlActv.CtrlSts1, network-representation={base-type=CtrlSts1_2, compu {0=CtrlSts1_NoCtrl, 1=CtrlSts1_InCtrl; unit Unitless}, "Anti Blocking Systems (ABS) control is active (at least one wheel) 0 = No wheel is in Anti Blocking Systems (ABS) control 1 = At least one wheel is in Anti Blocking Systems (ABS) control"}}, {leaf-element=AbsCtrlActv.Chks, network-representation={base-type=UInt8_2, compu {identical; unit Unitless}, "checksum"}}, {leaf-element=AbsCtrlActv.Cntr, network-representation={base-type=UInt4_2, compu {identical; unit Unitless}, "counter"}}], data-element=AbsCtrlActv, init-value=constant-reference=AbsCtrlActv_9}, required-interface=AbsCtrlActv_9
      CarModCrashSaved: nonqueued-receiver-com-spec{data-element=CarModCrashSaved, network-representation={base-type=NoYes1_2, compu {0=NoYes1_No, 1=NoYes1_Yes; unit Unitless}, "Boolean which states if Car Mode has been written to memory."}, init-value=constant-reference=CarModCrashSaved_4}, required-interface=CarModCrashSaved_4
      CarTiGlb: nonqueued-receiver-com-spec{data-element=CarTiGlb, network-representation={base-type=CarTiGlb_2, compu {phys=raw*0.1 for raw 0..4294967295; unit s}, "Presents a tiime value that shall be used by all ECUs to time-stamp diagnsotic trouble codes (DTC) according to the requirements for Global DTC snapshot data."}, init-value=constant-reference=CarTiGlb_5}, required-interface=CarTiGlb_5
      DoorLeReSts: nonqueued-receiver-com-spec{data-element=DoorLeReSts, network-representation={base-type=DoorSts2_2, compu {0=DoorSts2_Ukwn, 1=DoorSts2_Opend, 2=DoorSts2_Clsd; unit Unitless}, "DoorLeReSts - Left Rear Side Door Status. Ukwn - Unknown status Opend - Opened Clsd - Closed"}, init-value=constant-reference=DoorLeReSts_6}, required-interface=DoorLeReSts_6
      DoorDrvrSts: nonqueued-receiver-com-spec{data-element=DoorDrvrSts, network-representation={base-type=DoorSts2_2, compu {0=DoorSts2_Ukwn, 1=DoorSts2_Opend, 2=DoorSts2_Clsd; unit Unitless}, "DoorDrvrSts - Driver Door Status Ukwn - Unknown status Opend - Opened Clsd - Closed"}, init-value=constant-reference=DoorDrvrSts_5}, required-interface=DoorDrvrSts_5
      DoorRiReSts: nonqueued-receiver-com-spec{data-element=DoorRiReSts, network-representation={base-type=DoorSts2_2, compu {0=DoorSts2_Ukwn, 1=DoorSts2_Opend, 2=DoorSts2_Clsd; unit Unitless}, "DoorRiReSts - Right Rear Side Door Status Ukwn - Unknown status Opend - Opened Clsd - Closed"}, init-value=constant-reference=DoorRiReSts_6}, required-interface=DoorRiReSts_6
      DoorPassSts: nonqueued-receiver-com-spec{data-element=DoorPassSts, network-representation={base-type=DoorSts2_2, compu {0=DoorSts2_Ukwn, 1=DoorSts2_Opend, 2=DoorSts2_Clsd; unit Unitless}, "DoorPassSts - Passenger Door Status Ukwn - Unknown status Opend - Opened Clsd - Closed"}, init-value=constant-reference=DoorPassSts_5}, required-interface=DoorPassSts_5
      EscCtrlIndcn: nonqueued-receiver-com-spec{data-element=EscCtrlIndcn, network-representation={base-type=DevSts1_2, compu {0=DevSts1_On, 1=DevSts1_Off, 2=DevSts1_Flt; unit Unitless}, "Indicates that an Electronic stability control (ESC) controller is active"}, init-value=constant-reference=EscCtrlIndcn_8}, required-interface=EscCtrlIndcn_8
      PostImpctBrkgRdy: nonqueued-receiver-com-spec{data-element=PostImpctBrkgRdy, network-representation={base-type=PostImpctBrkgRdy_2, compu-method=PostImpctBrkgRdy_1, "Information regarding if Post Impact Braking support is available from VDDM."}, init-value=constant-reference=PostImpctBrkgRdy_5}, required-interface=PostImpctBrkgRdy_5
      RlyPwrDistbnCmd1WdIgnRlyCmd: nonqueued-receiver-com-spec{data-element=RlyPwrDistbnCmd1WdIgnRlyCmd, network-representation={base-type=OnOff1_2, compu {0=OnOff1_Off, 1=OnOff1_On; unit Unitless}, "Ignition relay status"}, init-value=constant-reference=RlyPwrDistbnCmd1WdIgnRlyCmd_6}, required-interface=RlyPwrDistbnCmd1WdIgnRlyCmd_6
      BrkPedlPsd: nonqueued-receiver-com-spec{composite-network-representations=[{leaf-element=BrkPedlPsd.BrkPedlPsd, network-representation={base-type=NoYes1_2, compu {0=NoYes1_No, 1=NoYes1_Yes; unit Unitless}, "Set to 1 if brake pedal is pressed, otherwise 0"}}, {leaf-element=BrkPedlPsd.BrkPedlPsdQf, network-representation={base-type=GenQf1_2, compu-method=GenQf1_1, "Quality factor"}}, {leaf-element=BrkPedlPsd.BrkPedlPsdCntr, network-representation={base-type=UInt4_2, compu {identical; unit Unitless}, "Counter"}}, {leaf-element=BrkPedlPsd.BrkPedlPsdChks, network-representation={base-type=UInt8_2, compu {identical; unit Unitless}, "Checksum"}}, {leaf-element=BrkPedlPsd.BrkPedlNotPsdSafe, network-representation={base-type=NoYes1_2, compu {0=NoYes1_No, 1=NoYes1_Yes; unit Unitless}, "Set to 1 if brake pedal is not pressed, otherwise 0"}}], data-element=BrkPedlPsd, init-value=constant-reference=BrkPedlPsd_7}, required-interface=BrkPedlPsd_7
      EscSt: nonqueued-receiver-com-spec{composite-network-representations=[{leaf-element=EscSt.EscSt, network-representation={base-type=EscSt1_2, compu-method=EscSt1_1, "Information on activation/ deactivation of Electronic Stability Control (ESC) Esc state information for Esc ON, Esc OFF or Esc Sport"}}, {leaf-element=EscSt.EscStChks, network-representation={base-type=UInt8_2, compu {identical; unit Unitless}, "Information on activation/ deactivation of Electronic Stability Control (ESC) Checksum for Esc state"}}, {leaf-element=EscSt.EscStCntr, network-representation={base-type=UInt4_2, compu {identical; unit Unitless}, "Information on activation/ deactivation of Electronic Stability Control (ESC) Counter for Esc state"}}], data-element=EscSt, init-value=constant-reference=EscSt_8}, required-interface=EscSt_8
      VehBattU: nonqueued-receiver-com-spec{composite-network-representations=[{leaf-element=VehBattU.SysU, network-representation={base-type=U1_2, compu {phys=raw*0.1 for raw 0..250; unit Volt}, "Vehicle System Voltage At 12V side"}}, {leaf-element=VehBattU.SysUQf, network-representation={base-type=GenQf1_2, compu-method=GenQf1_1, "Present vehicle voltage measured by CEM with QF"}}], data-element=VehBattU, init-value=constant-reference=VehBattU_8}, required-interface=VehBattU_8
      VehCfgPrm: nonqueued-receiver-com-spec{composite-network-representations=[{leaf-element=VehCfgPrm.BlkIDBytePosn1, network-representation={base-type=Nr2_3, compu {phys=raw for raw 0..255; unit Unitless}, "signal block counter."}}, {leaf-element=VehCfgPrm.CCPBytePosn2, network-representation={base-type=Nr2_3, compu {phys=raw for raw 0..255; unit Unitless}, "(BlockID-1)*7 + 1."}}, {leaf-element=VehCfgPrm.CCPBytePosn3, network-representation={base-type=Nr2_3, compu {phys=raw for raw 0..255; unit Unitless}, "(BlockID-1)*7 + 2."}}, {leaf-element=VehCfgPrm.CCPBytePosn4, network-representation={base-type=Nr2_3, compu {phys=raw for raw 0..255; unit Unitless}, "(BlockID-1)*7 + 3."}}, {leaf-element=VehCfgPrm.CCPBytePosn5, network-representation={base-type=Nr2_3, compu {phys=raw for raw 0..255; unit Unitless}, "(BlockID-1)*7 + 4."}}, {leaf-element=VehCfgPrm.CCPBytePosn6, network-representation={base-type=Nr2_3, compu {phys=raw for raw 0..255; unit Unitless}, "(BlockID-1)*7 + 5."}}, {leaf-element=VehCfgPrm.CCPBytePosn7, network-representation={base-type=Nr2_3, compu {phys=raw for raw 0..255; unit Unitless}, "(BlockID-1)*7 + 6."}}, {leaf-element=VehCfgPrm.CCPBytePosn8, network-representation={base-type=Nr2_3, compu {phys=raw for raw 0..255; unit Unitless}, "(BlockID-1)*7 + 7."}}], data-element=VehCfgPrm, init-value=constant-reference=VehCfgPrm_5}, required-interface=VehCfgPrm_5
      Vin: nonqueued-receiver-com-spec{composite-network-representations=[{leaf-element=Vin.BlockNr, network-representation={base-type=Nr2_3, compu {phys=raw for raw 0..255; unit Unitless}, "VIN number block counter."}}, {leaf-element=Vin.VINSignalPos1, network-representation={base-type=Nr2_3, compu {phys=raw for raw 0..255; unit Unitless}, "VIN byte 1. Used for character 1, 8 and 15."}}, {leaf-element=Vin.VINSignalPos2, network-representation={base-type=Nr2_3, compu {phys=raw for raw 0..255; unit Unitless}, "VIN byte 2. Used for character 2, 9 and 16."}}, {leaf-element=Vin.VINSignalPos3, network-representation={base-type=Nr2_3, compu {phys=raw for raw 0..255; unit Unitless}, "VIN byte 3. Used for character 3, 10 and 17."}}, {leaf-element=Vin.VINSignalPos4, network-representation={base-type=Nr2_3, compu {phys=raw for raw 0..255; unit Unitless}, "VIN byte 4. Used for character 4 and 11."}}, {leaf-element=Vin.VINSignalPos5, network-representation={base-type=Nr2_3, compu {phys=raw for raw 0..255; unit Unitless}, "VIN byte 5. Used for character 5 and 12."}}, {leaf-element=Vin.VINSignalPos6, network-representation={base-type=Nr2_3, compu {phys=raw for raw 0..255; unit Unitless}, "VIN byte 6. Used for character 6 and 13."}}, {leaf-element=Vin.VINSignalPos7, network-representation={base-type=Nr2_3, compu {phys=raw for raw 0..255; unit Unitless}, "VIN byte 7. Used for character 7 and 14."}}], data-element=Vin, init-value=constant-reference=Vin_6}, required-interface=Vin_6
      VehMtnSt: nonqueued-receiver-com-spec{composite-network-representations=[{leaf-element=VehMtnSt.VehMtnSt, network-representation={base-type=VehMtnSt2_2, compu-method=VehMtnSt2_1, "Vehicle motion state information based on wheel speed sensors. Provides information about vehicle stand still and vehicle rolling direction. Vehicle motion state"}}, {leaf-element=VehMtnSt.VehMtnStChks, network-representation={base-type=UInt8_2, compu {identical; unit Unitless}, "Vehicle motion state information based on wheel speed sensors. Provides information about vehicle stand still and vehicle rolling direction. Checksum for vehicle motion state"}}, {leaf-element=VehMtnSt.VehMtnStCntr, network-representation={base-type=UInt4_2, compu {identical; unit Unitless}, "Vehicle motion state information based on wheel speed sensors. Provides information about vehicle stand still and vehicle rolling direction. Counter for vehicle motion state"}}], data-element=VehMtnSt, uses-end-to-end-protection=true, init-value=constant-reference=VehMtnSt_10}, required-interface=VehMtnSt_10
      VehSpdLgt: nonqueued-receiver-com-spec{composite-network-representations=[{leaf-element=VehSpdLgt.VehSpdLgtA, network-representation={base-type=Spd1_2, compu {phys=raw*0.00391 for raw 0..31970; unit m/s}, "Vehicle speed longitudinal based on wheel speed sensors and longitudinal acceleration."}}, {leaf-element=VehSpdLgt.VehSpdLgtQf, network-representation={base-type=GenQf1_2, compu-method=GenQf1_1, "Quality factor for vehicle speed as measured by wheel speed sensors and longitudinal acceleration."}}, {leaf-element=VehSpdLgt.VehSpdLgtCntr, network-representation={base-type=UInt4_2, compu {identical; unit Unitless}, "Counter"}}, {leaf-element=VehSpdLgt.VehSpdLgtChks, network-representation={base-type=UInt8_2, compu {identical; unit Unitless}, "Checksum"}}], data-element=VehSpdLgt, uses-end-to-end-protection=true, init-value=constant-reference=VehSpdLgt_15}, required-interface=VehSpdLgt_15
      VehCfgPrmExt: nonqueued-receiver-com-spec{composite-network-representations=[{leaf-element=VehCfgPrmExt.BlkIDBytePosn1, network-representation={base-type=Nr2_3, compu {phys=raw for raw 0..255; unit Unitless}, "CarConfigExtended BlockID"}}, {leaf-element=VehCfgPrmExt.CCPBytePosn2, network-representation={base-type=Nr2_3, compu {phys=raw for raw 0..255; unit Unitless}, "CarConfigExtended BytePos2"}}, {leaf-element=VehCfgPrmExt.CCPBytePosn3, network-representation={base-type=Nr2_3, compu {phys=raw for raw 0..255; unit Unitless}, "CarConfigExtended BytePos3"}}, {leaf-element=VehCfgPrmExt.CCPBytePosn4, network-representation={base-type=Nr2_3, compu {phys=raw for raw 0..255; unit Unitless}, "CarConfigExtended BytePos4"}}, {leaf-element=VehCfgPrmExt.CCPBytePosn5, network-representation={base-type=Nr2_3, compu {phys=raw for raw 0..255; unit Unitless}, "CarConfigExtended BytePos5"}}, {leaf-element=VehCfgPrmExt.CCPBytePosn6, network-representation={base-type=Nr2_3, compu {phys=raw for raw 0..255; unit Unitless}, "CarConfigExtended BytePos6"}}, {leaf-element=VehCfgPrmExt.CCPBytePosn7, network-representation={base-type=Nr2_3, compu {phys=raw for raw 0..255; unit Unitless}, "CarConfigExtended BytePos7"}}, {leaf-element=VehCfgPrmExt.CCPBytePosn8, network-representation={base-type=Nr2_3, compu {phys=raw for raw 0..255; unit Unitless}, "CarConfigExtended BytePos8"}}], data-element=VehCfgPrmExt, init-value=constant-reference=VehCfgPrmExt_2}, required-interface=VehCfgPrmExt_2
      AccrPedlRat: nonqueued-receiver-com-spec{composite-network-representations=[{leaf-element=AccrPedlRat.AccrPedlRat, network-representation={base-type=Perc1_2, compu {phys=raw/256 for raw 0..25600; unit %}, "Accelerator Pedal Position with adapted 0 point. Value as percentage of fully pressed pedal"}}, {leaf-element=AccrPedlRat.Cntr, network-representation={base-type=UInt4_2, compu {identical; unit Unitless}, "Accelerator Pedal Position with adapted 0 point. Value as percentage of fully pressed pedal. Counter"}}, {leaf-element=AccrPedlRat.Chks, network-representation={base-type=UInt8_2, compu {identical; unit Unitless}, "Accelerator Pedal Position with adapted 0 point. Value as percentage of fully pressed pedal. Checksum"}}], data-element=AccrPedlRat, init-value=constant-reference=AccrPedlRat_7}, required-interface=AccrPedlRat_7
      AmbTIndcdWithUnit: nonqueued-receiver-com-spec{composite-network-representations=[{leaf-element=AmbTIndcdWithUnit.AmbTIndcd, network-representation={base-type=AmbTIndcd_2, compu {phys=raw*0.1-100 for raw 0..4095; unit Unitless}, "Indicated ambient temperature"}}, {leaf-element=AmbTIndcdWithUnit.AmbTIndcdUnit, network-representation={base-type=AmbTIndcdUnit_2, compu-method=AmbTIndcdUnit_1, "Unit of the indicated temperature"}}, {leaf-element=AmbTIndcdWithUnit.QF, network-representation={base-type=GenQf1_2, compu-method=GenQf1_1, "QF"}}], data-element=AmbTIndcdWithUnit, init-value=constant-reference=AmbTIndcdWithUnit_3}, required-interface=AmbTIndcdWithUnit_3
      BkpOfDstTrvld: nonqueued-receiver-com-spec{data-element=BkpOfDstTrvld, network-representation={base-type=Len31_2, compu {phys=raw for raw 0..2000000; unit km}, "total traveled distance."}, alive-timeout=1.0, init-value=constant-reference=BkpOfDstTrvld_7}, required-interface=BkpOfDstTrvld_7
      ReqForPassAirbIndcnAckd: nonqueued-receiver-com-spec{data-element=ReqForPassAirbIndcnAckd, network-representation={base-type=ReqForPassAirbIndcnAckd_2, compu-method=ReqForPassAirbIndcnAckd_1, "info about the acknowledgement"}, init-value=constant-reference=ReqForPassAirbIndcnAckd_2}, required-interface=ReqForPassAirbIndcnAckd_2
      BrkSysCylPMst: nonqueued-receiver-com-spec{composite-network-representations=[{leaf-element=BrkSysCylPMst.Act, network-representation={base-type=P33_2, compu {phys=raw*0.3-30 for raw 0..1022; unit bar}, "Brake system master cylinder pressure information Actual pressure, raw value"}}, {leaf-element=BrkSysCylPMst.ActQf, network-representation={base-type=GenQf1_2, compu-method=GenQf1_1, "Brake system master cylinder pressure information Actual pressure quality factor"}}, {leaf-element=BrkSysCylPMst.Tar, network-representation={base-type=P35_2, compu {phys=raw*0.25 for raw 0..1000; unit bar}, "Brake system master cylinder pressure information Target pressure"}}, {leaf-element=BrkSysCylPMst.Virt, network-representation={base-type=P35_2, compu {phys=raw*0.25 for raw 0..1000; unit bar}, "Brake system master cylinder pressure information Virtual pressure"}}, {leaf-element=BrkSysCylPMst.VirtQf, network-representation={base-type=GenQf1_2, compu-method=GenQf1_1, "Brake system master cylinder pressure information Virtual pressure quality factor"}}, {leaf-element=BrkSysCylPMst.Chks, network-representation={base-type=UInt8_2, compu {identical; unit Unitless}, "Brake system master cylinder pressure information Checksum"}}, {leaf-element=BrkSysCylPMst.Cntr, network-representation={base-type=UInt4_2, compu {identical; unit Unitless}, "Brake system master cylinder pressure information Counter"}}], data-element=BrkSysCylPMst, init-value=constant-reference=BrkSysCylPMst_7}, required-interface=BrkSysCylPMst_7
      AccrpedlSts: nonqueued-receiver-com-spec{composite-network-representations=[{leaf-element=AccrpedlSts.FltSts, network-representation={base-type=Flt_3, compu {0=Flt_NoFault, 1=Flt_Fault; unit Unitless}, "It should provide acceleration pedal Status signal ( AccrpedlSts ) to predict whether the accelerator pedal has fault or not.1-Fault; 0-NoFault"}}, {leaf-element=AccrpedlSts.Chks, network-representation={base-type=UInt8_2, compu {identical; unit Unitless}, "It should provide acceleration pedal Status signal ( AccrpedlSts ) to predict whether the accelerator pedal has fault or not.1-Fault; 0-NoFault"}}, {leaf-element=AccrpedlSts.Cntr, network-representation={base-type=UInt4_2, compu {identical; unit Unitless}, "It should provide acceleration pedal Status signal ( AccrpedlSts ) to predict whether the accelerator pedal has fault or not.1-Fault; 0-NoFault"}}], data-element=AccrpedlSts, init-value=constant-reference=AccrpedlSts_6}, required-interface=AccrpedlSts_6
      PassAirbLampStsRec: nonqueued-receiver-com-spec{composite-network-representations=[{leaf-element=PassAirbLampStsRec.PassAirbLampSts, network-representation={base-type=PassAirbLampSts1_2, compu-method=PassAirbLampSts1_1, "Signals if there is a HW fault, SW fault or signaling fault related to the PAD and PAE indication lamps."}}, {leaf-element=PassAirbLampStsRec.PassAirbLampStsChks, network-representation={base-type=UInt8_2, compu {identical; unit Unitless}, "Ones complement of the data and counter in the signal group."}}, {leaf-element=PassAirbLampStsRec.PassAirbLampStsCntr, network-representation={base-type=UInt4_2, compu {identical; unit Unitless}, "Counter that increases for each updated (not necessarily changed) value."}}], data-element=PassAirbLampStsRec, uses-end-to-end-protection=true, init-value=constant-reference=PassAirbLampStsRec_5}, required-interface=PassAirbLampStsRec_5
      EngN2: nonqueued-receiver-com-spec{data-element=EngN2, network-representation={base-type=N30_2, compu {phys=raw*0.5 for raw 0..32767; unit rpm}, "Engine Speed [rpm]"}, init-value=constant-reference=EngN2_4}, required-interface=EngN2_4
      ThrPos: nonqueued-receiver-com-spec{data-element=ThrPos, network-representation={base-type=Perc2_2, compu {phys=raw*0.5 for raw 0..200; unit %}, "ECM throttle position (AbsThrottlePosition) on CAN"}, init-value=constant-reference=ThrPos_3}, required-interface=ThrPos_3
      DoorDrvrLockSts: nonqueued-receiver-com-spec{data-element=DoorDrvrLockSts, network-representation={base-type=LockSts2_2, compu-method=LockSts2_1, "DoorDrvrLockSts - Driver Door Lock Status Lock status LockStsUkwn - Lock Status Unknown Unlckd - Unlocked Lockd - Locked SafeLockd - Safe Locked (Double Locked)"}, init-value=constant-reference=DoorDrvrLockSts_5}, required-interface=DoorDrvrLockSts_5
      DoorLeReLockSts: nonqueued-receiver-com-spec{data-element=DoorLeReLockSts, network-representation={base-type=LockSts2_2, compu-method=LockSts2_1, "DoorLeReLockSts - Left Rear Door Lock Status Lock status LockStsUkwn - Lock Status Unknown Unlckd - Unlocked Lockd - Locked SafeLockd - Safe Locked (Double Locked)"}, init-value=constant-reference=DoorLeReLockSts_6}, required-interface=DoorLeReLockSts_6
      DoorPassLockSts: nonqueued-receiver-com-spec{data-element=DoorPassLockSts, network-representation={base-type=LockSts2_2, compu-method=LockSts2_1, "DoorPassLockSts - Passenger Door Lock Status Lock status LockStsUkwn - Lock Status Unknown Unlckd - Unlocked Lockd - Locked SafeLockd - Safe Locked (Double Locked)"}, init-value=constant-reference=DoorPassLockSts_5}, required-interface=DoorPassLockSts_5
      DoorRiReLockSts: nonqueued-receiver-com-spec{data-element=DoorRiReLockSts, network-representation={base-type=LockSts2_2, compu-method=LockSts2_1, "DoorRiReLockSts - Right Rear Door Lock Status Lock status LockStsUkwn - Lock Status Unknown Unlckd - Unlocked Lockd - Locked SafeLockd - Safe Locked (Double Locked)"}, init-value=constant-reference=DoorRiReLockSts_6}, required-interface=DoorRiReLockSts_6
      PosnBrief: nonqueued-receiver-com-spec{composite-network-representations=[{leaf-element=PosnBrief.PosnLat, network-representation={base-type=PosnLat_2, compu {phys=raw/3600000 for raw -324000000..324000000; unit Deg}, "Latitude"}}, {leaf-element=PosnBrief.PosnLgt, network-representation={base-type=PosnLgt_2, compu {phys=raw/3600000 for raw -648000000..648000000; unit Deg}, "Longitude"}}], data-element=PosnBrief, init-value=constant-reference=PosnBrief_3}, required-interface=PosnBrief_3
      AbsSts: nonqueued-receiver-com-spec{data-element=AbsSts, network-representation={base-type=DevErrSts2_2, compu {0=DevErrSts2_NoFlt, 1=DevErrSts2_Flt; unit Unitless}, "Indicates if the ABS function is temporarily or permantly disabled due to a failure."}, init-value=constant-reference=AbsSts_6}, required-interface=AbsSts_6
      BrkAndAbsWarnIndcnReq: nonqueued-receiver-com-spec{composite-network-representations=[{leaf-element=BrkAndAbsWarnIndcnReq.BrkWarnIndcnReq, network-representation={base-type=OnOff2_2, compu {0=OnOff2_On, 1=OnOff2_Off; unit Unitless}, "Request for warning indication to driver in case of brake failure (red warning) or ABS failure (yellow warning) Brake warning indication request"}}, {leaf-element=BrkAndAbsWarnIndcnReq.AbsWarnIndcnReq, network-representation={base-type=AbsWarnIndcnReq_2, compu-method=AbsWarnIndcnReq_1, "Request for warning indication to driver in case of brake failure (red warning) or ABS failure (yellow warning) ABS warning indication request"}}, {leaf-element=BrkAndAbsWarnIndcnReq.BrkAndAbsWarnIndcnReqChks, network-representation={base-type=UInt8_2, compu {identical; unit Unitless}, "Request for warning indication to driver in case of brake failure (red warning) or ABS failure (yellow warning) Checksum for Brake and ABS warning indication request"}}, {leaf-element=BrkAndAbsWarnIndcnReq.BrkAndAbsWarnIndcnReqCntr, network-representation={base-type=UInt4_2, compu {identical; unit Unitless}, "Request for warning indication to driver in case of brake failure (red warning) or ABS failure (yellow warning) Counter for Brake and ABS warning indication request"}}], data-element=BrkAndAbsWarnIndcnReq, init-value=constant-reference=BrkAndAbsWarnIndcnReq_7}, required-interface=BrkAndAbsWarnIndcnReq_7
      VehModMngtGlbSafe1: nonqueued-receiver-com-spec{composite-network-representations=[{leaf-element=VehModMngtGlbSafe1.UsgModSts, network-representation={base-type=UsgModSts1_2, compu-method=UsgModSts1_1, "UsageMode Status"}}, {leaf-element=VehModMngtGlbSafe1.CarModSts1, network-representation={base-type=CarModSts1_2, compu-method=CarModSts1_1, "CarMode Status"}}, {leaf-element=VehModMngtGlbSafe1.CarModSubtypWdCarModSubtyp, network-representation={base-type=Nr5_2, compu {identical; unit Unitless}, "CarMode substate status"}}, {leaf-element=VehModMngtGlbSafe1.EgyLvlElecMai, network-representation={base-type=UInt4_2, compu {identical; unit Unitless}, "Main energy level in the vehicle."}}, {leaf-element=VehModMngtGlbSafe1.EgyLvlElecSubtyp, network-representation={base-type=UInt4_2, compu {identical; unit Unitless}, "Substate of the energy level in the vehicle."}}, {leaf-element=VehModMngtGlbSafe1.PwrLvlElecMai, network-representation={base-type=UInt4_2, compu {identical; unit Unitless}, "Main Power level in the vehicle."}}, {leaf-element=VehModMngtGlbSafe1.PwrLvlElecSubtyp, network-representation={base-type=UInt4_2, compu {identical; unit Unitless}, "Substate of the power level in the vehicle."}}, {leaf-element=VehModMngtGlbSafe1.FltEgyCnsWdSts, network-representation={base-type=FltEgyCns1_2, compu {0=FltEgyCns1_NoFlt, 1=FltEgyCns1_Flt; unit Unitless}, "High quiescent current detected by CEM via BMS."}}, {leaf-element=VehModMngtGlbSafe1.Chks, network-representation={base-type=UInt8_2, compu {identical; unit Unitless}, "Checksum"}}, {leaf-element=VehModMngtGlbSafe1.Cntr, network-representation={base-type=UInt4_2, compu {identical; unit Unitless}, "Counter"}}], data-element=VehModMngtGlbSafe1, uses-end-to-end-protection=true, alive-timeout=1.0, init-value=constant-reference=VehModMngtGlbSafe1_7}, required-interface=VehModMngtGlbSafe1_7
      LeFrntTireMsg: nonqueued-receiver-com-spec{composite-network-representations=[{leaf-element=LeFrntTireMsg.PWarnFlg, network-representation={base-type=PWarnFlg_2, compu-method=PWarnFlg_2, "pressure warn flag"}}, {leaf-element=LeFrntTireMsg.TWarnFlg, network-representation={base-type=Normalwarning_2, compu {0=Normalwarning_Normal, 1=Normalwarning_Warning; unit Unitless}, "temperature warn flag"}}, {leaf-element=LeFrntTireMsg.SysWarnFlg, network-representation={base-type=Normalwarning_2, compu {0=Normalwarning_Normal, 1=Normalwarning_Warning; unit Unitless}, "system warn flag"}}, {leaf-element=LeFrntTireMsg.FastLoseWarnFlg, network-representation={base-type=Normalwarning_2, compu {0=Normalwarning_Normal, 1=Normalwarning_Warning; unit Unitless}, "fast lost warn flag"}}, {leaf-element=LeFrntTireMsg.BattLoSt, network-representation={base-type=Normalwarning_2, compu {0=Normalwarning_Normal, 1=Normalwarning_Warning; unit Unitless}, "battery low status"}}, {leaf-element=LeFrntTireMsg.MsgOldFlg, network-representation={base-type=Normalwarning_2, compu {0=Normalwarning_Normal, 1=Normalwarning_Warning; unit Unitless}, "message old flag"}}, {leaf-element=LeFrntTireMsg.TireFillgAssiPSts, network-representation={base-type=Normalwarning_2, compu {0=Normalwarning_Normal, 1=Normalwarning_Warning; unit Unitless}, "tire fill status"}}, {leaf-element=LeFrntTireMsg.T, network-representation={base-type=T8_1, compu {phys=raw-50 for raw 0..255; unit degC}, "tire pressure"}}, {leaf-element=LeFrntTireMsg.P, network-representation={base-type=Kpa8_1, compu {phys=raw*1.373 for raw 0..255; unit KiloPa}, "tire temperature"}}], data-element=LeFrntTireMsg, init-value=constant-reference=LeFrntTireMsg_6}, required-interface=LeFrntTireMsg_6
      RiFrntTireMsg: nonqueued-receiver-com-spec{composite-network-representations=[{leaf-element=RiFrntTireMsg.PWarnFlg, network-representation={base-type=PWarnFlg_2, compu-method=PWarnFlg_2, "pressure warn flag"}}, {leaf-element=RiFrntTireMsg.TWarnFlg, network-representation={base-type=Normalwarning_2, compu {0=Normalwarning_Normal, 1=Normalwarning_Warning; unit Unitless}, "temperature warn flag"}}, {leaf-element=RiFrntTireMsg.SysWarnFlg, network-representation={base-type=Normalwarning_2, compu {0=Normalwarning_Normal, 1=Normalwarning_Warning; unit Unitless}, "system warn flag"}}, {leaf-element=RiFrntTireMsg.FastLoseWarnFlg, network-representation={base-type=Normalwarning_2, compu {0=Normalwarning_Normal, 1=Normalwarning_Warning; unit Unitless}, "fast lost warn flag"}}, {leaf-element=RiFrntTireMsg.BattLoSt, network-representation={base-type=Normalwarning_2, compu {0=Normalwarning_Normal, 1=Normalwarning_Warning; unit Unitless}, "battery low status"}}, {leaf-element=RiFrntTireMsg.MsgOldFlg, network-representation={base-type=Normalwarning_2, compu {0=Normalwarning_Normal, 1=Normalwarning_Warning; unit Unitless}, "message old flag"}}, {leaf-element=RiFrntTireMsg.TireFillgAssiPSts, network-representation={base-type=Normalwarning_2, compu {0=Normalwarning_Normal, 1=Normalwarning_Warning; unit Unitless}, "tire fill status"}}, {leaf-element=RiFrntTireMsg.T, network-representation={base-type=T8_1, compu {phys=raw-50 for raw 0..255; unit degC}, "tire pressure"}}, {leaf-element=RiFrntTireMsg.P, network-representation={base-type=Kpa8_1, compu {phys=raw*1.373 for raw 0..255; unit KiloPa}, "tire temperature"}}], data-element=RiFrntTireMsg, init-value=constant-reference=RiFrntTireMsg_5}, required-interface=RiFrntTireMsg_5
      LeReTireMsg: nonqueued-receiver-com-spec{composite-network-representations=[{leaf-element=LeReTireMsg.PWarnFlg, network-representation={base-type=PWarnFlg_2, compu-method=PWarnFlg_2, "pressure warn flag"}}, {leaf-element=LeReTireMsg.TWarnFlg, network-representation={base-type=Normalwarning_2, compu {0=Normalwarning_Normal, 1=Normalwarning_Warning; unit Unitless}, "temperature warn flag"}}, {leaf-element=LeReTireMsg.SysWarnFlg, network-representation={base-type=Normalwarning_2, compu {0=Normalwarning_Normal, 1=Normalwarning_Warning; unit Unitless}, "system warn flag"}}, {leaf-element=LeReTireMsg.FastLoseWarnFlg, network-representation={base-type=Normalwarning_2, compu {0=Normalwarning_Normal, 1=Normalwarning_Warning; unit Unitless}, "fast lost warn flag"}}, {leaf-element=LeReTireMsg.BattLoSt, network-representation={base-type=Normalwarning_2, compu {0=Normalwarning_Normal, 1=Normalwarning_Warning; unit Unitless}, "battery low status"}}, {leaf-element=LeReTireMsg.MsgOldFlg, network-representation={base-type=Normalwarning_2, compu {0=Normalwarning_Normal, 1=Normalwarning_Warning; unit Unitless}, "message old flag"}}, {leaf-element=LeReTireMsg.TireFillgAssiPSts, network-representation={base-type=Normalwarning_2, compu {0=Normalwarning_Normal, 1=Normalwarning_Warning; unit Unitless}, "tire fill status"}}, {leaf-element=LeReTireMsg.T, network-representation={base-type=T8_1, compu {phys=raw-50 for raw 0..255; unit degC}, "tire pressure"}}, {leaf-element=LeReTireMsg.P, network-representation={base-type=Kpa8_1, compu {phys=raw*1.373 for raw 0..255; unit KiloPa}, "tire temperature"}}], data-element=LeReTireMsg, init-value=constant-reference=LeReTireMsg_6}, required-interface=LeReTireMsg_6
      RiReTireMsg: nonqueued-receiver-com-spec{composite-network-representations=[{leaf-element=RiReTireMsg.PWarnFlg, network-representation={base-type=PWarnFlg_2, compu-method=PWarnFlg_2, "pressure warn flag"}}, {leaf-element=RiReTireMsg.TWarnFlg, network-representation={base-type=Normalwarning_2, compu {0=Normalwarning_Normal, 1=Normalwarning_Warning; unit Unitless}, "temperature warn flag"}}, {leaf-element=RiReTireMsg.SysWarnFlg, network-representation={base-type=Normalwarning_2, compu {0=Normalwarning_Normal, 1=Normalwarning_Warning; unit Unitless}, "system warn flag"}}, {leaf-element=RiReTireMsg.FastLoseWarnFlg, network-representation={base-type=Normalwarning_2, compu {0=Normalwarning_Normal, 1=Normalwarning_Warning; unit Unitless}, "fast lost warn flag"}}, {leaf-element=RiReTireMsg.BattLoSt, network-representation={base-type=Normalwarning_2, compu {0=Normalwarning_Normal, 1=Normalwarning_Warning; unit Unitless}, "battery low status"}}, {leaf-element=RiReTireMsg.MsgOldFlg, network-representation={base-type=Normalwarning_2, compu {0=Normalwarning_Normal, 1=Normalwarning_Warning; unit Unitless}, "message old flag"}}, {leaf-element=RiReTireMsg.TireFillgAssiPSts, network-representation={base-type=Normalwarning_2, compu {0=Normalwarning_Normal, 1=Normalwarning_Warning; unit Unitless}, "tire fill status"}}, {leaf-element=RiReTireMsg.T, network-representation={base-type=T8_1, compu {phys=raw-50 for raw 0..255; unit degC}, "tire pressure"}}, {leaf-element=RiReTireMsg.P, network-representation={base-type=Kpa8_1, compu {phys=raw*1.373 for raw 0..255; unit KiloPa}, "tire temperature"}}], data-element=RiReTireMsg, init-value=constant-reference=RiReTireMsg_6}, required-interface=RiReTireMsg_6
      AsyALgtSts: nonqueued-receiver-com-spec{composite-network-representations=[{leaf-element=AsyALgtSts.AsyALgtSts, network-representation={base-type=AsyALgtSts_4, compu-method=AsyALgtSts_4, "The signal indicates the status of the longitudinal control; off, passive, standby, active etc."}}, {leaf-element=AsyALgtSts.Cntr, network-representation={base-type=UInt4_2, compu {identical; unit Unitless}, "counter for E2E"}}, {leaf-element=AsyALgtSts.Chks, network-representation={base-type=UInt8_2, compu {identical; unit Unitless}, "check sum for E2E"}}], data-element=AsyALgtSts, init-value=constant-reference=AsyALgtSts_5}, required-interface=AsyALgtSts_5
      CrsCtrlrSts: nonqueued-receiver-com-spec{data-element=CrsCtrlrSts, network-representation={base-type=CrsCtrlrSts1_2, compu-method=CrsCtrlrSts1_1, "The signal indicates the status (or state) of the Cruise Controller; Off, Standby, Actv etc."}, init-value=constant-reference=CrsCtrlrSts_3}, required-interface=CrsCtrlrSts_3
      DispOfPrpsnModForEv: nonqueued-receiver-com-spec{data-element=DispOfPrpsnModForEv, network-representation={base-type=DispOfPrpsnModForEv_2, compu-method=DispOfPrpsnModForEv_2, "Actual powertrain propulsion mode of the BEV propulsion system. Usage: For BEV power flow status display in HMI."}, init-value=constant-reference=DispOfPrpsnModForEv_2}, required-interface=DispOfPrpsnModForEv_2
      VehTiAndData: nonqueued-receiver-com-spec{composite-network-representations=[{leaf-element=VehTiAndData.Yr1, network-representation={base-type=Yr1_2, compu {identical; unit Year}, "Vehicle time (Hr, Min and Sec) and date (Year, Months and days) data for indication. See requirement for more information about the signals. Year, 0-99"}}, {leaf-element=VehTiAndData.Mth1, network-representation={base-type=Mth1_2, compu {identical; unit Month}, "Vehicle time (Hr, Min and Sec) and date (Year, Months and days) data for indication. See requirement for more information about the signals. Month, 1-12"}}, {leaf-element=VehTiAndData.Day, network-representation={base-type=Day1_2, compu {identical; unit Days}, "Vehicle time (Hr, Min and Sec) and date (Year, Months and days) data for indication. See requirement for more information about the signals. Day"}}, {leaf-element=VehTiAndData.Hr1, network-representation={base-type=Hr1_2, compu {identical; unit hours}, "Vehicle time (Hr, Min and Sec) and date (Year, Months and days) data for indication. See requirement for more information about the signals. Hour"}}, {leaf-element=VehTiAndData.Mins1, network-representation={base-type=Mins1_2, compu {identical; unit Mins}, "Vehicle time (Hr, Min and Sec) and date (Year, Months and days) data for indication. See requirement for more information about the signals. Minutes"}}, {leaf-element=VehTiAndData.Sec1, network-representation={base-type=Sec1_2, compu {identical; unit s}, "Vehicle time (Hr, Min and Sec) and date (Year, Months and days) data for indication. See requirement for more information about the signals. Seconds"}}, {leaf-element=VehTiAndData.DataValid, network-representation={base-type=NoYes1_2, compu {0=NoYes1_No, 1=NoYes1_Yes; unit Unitless}, "Vehicle time (Hr, Min and Sec) and date (Year, Months and days) data for indication. See requirement for more information about the signals. Signal qualifier, No means values should be ignored."}}], data-element=VehTiAndData, init-value=constant-reference=VehTiAndData_4}, required-interface=VehTiAndData_4
      TrsmActrPosnSafe: nonqueued-receiver-com-spec{composite-network-representations=[{leaf-element=TrsmActrPosnSafe.TrsmActrPosn, network-representation={base-type=TrsmActrPosn1_2, compu-method=TrsmActrPosn1_1, "Describes the transmission position (P, R, N, D). Can also take intermediate positions (PR, RN, ND). If error are detected on position sensors undefined is set. Transmission measured gear lever position"}}, {leaf-element=TrsmActrPosnSafe.TrsmActrPosnChks, network-representation={base-type=UInt8_2, compu {identical; unit Unitless}, "Describes the transmission position (P, R, N, D). Can also take intermediate positions (PR, RN, ND). If error are detected on position sensors undefined is set. Transmission measured gear lever position"}}, {leaf-element=TrsmActrPosnSafe.TrsmActrPosnCntr, network-representation={base-type=UInt4_2, compu {identical; unit Unitless}, "Describes the transmission position (P, R, N, D). Can also take intermediate positions (PR, RN, ND). If error are detected on position sensors undefined is set. Transmission measured gear lever position"}}], data-element=TrsmActrPosnSafe, init-value=constant-reference=TrsmActrPosnSafe_6}, required-interface=TrsmActrPosnSafe_6
      GearLvrIndcn: nonqueued-receiver-com-spec{data-element=GearLvrIndcn, network-representation={base-type=GearLvrIndcn2_2, compu-method=GearLvrIndcn2_1, "Gear lever indication (drivetrain position) to the driver. If drivetrain position is not possible to decide signal is set to undefined. Valid for automatic vehicles."}, init-value=constant-reference=GearLvrIndcn_6}, required-interface=GearLvrIndcn_6
      AsyAutDrvCtrlTyp: nonqueued-receiver-com-spec{data-element=AsyAutDrvCtrlTyp, network-representation={base-type=AsyAutDrvCtrlTyp_4, compu-method=AsyAutDrvCtrlTyp_4, "Indicates if autonomous driving is ACC/TJA/HWA/TJP or only ACC."}, init-value=constant-reference=AsyAutDrvCtrlTyp_7}, required-interface=AsyAutDrvCtrlTyp_7
      DrvrCrsCtrlFctSeld: nonqueued-receiver-com-spec{data-element=DrvrCrsCtrlFctSeld, network-representation={base-type=DrvrCrsCtrlFctSeldTyp_5, compu-method=DrvrCrsCtrlFctSeldTyp_4, "select ACC function or CC function."}, init-value=constant-reference=DrvrCrsCtrlFctSeld_8}, required-interface=DrvrCrsCtrlFctSeld_8
      CrsCtrlrStbOk: nonqueued-receiver-com-spec{data-element=CrsCtrlrStbOk, network-representation={base-type=OnOff1_2, compu {0=OnOff1_Off, 1=OnOff1_On; unit Unitless}, "The signal informs if the Cruise Controller can be set to standby or not."}, init-value=constant-reference=CrsCtrlrStbOk_2}, required-interface=CrsCtrlrStbOk_2
      CrsCtrlrActvnOk: nonqueued-receiver-com-spec{data-element=CrsCtrlrActvnOk, network-representation={base-type=OnOff1_2, compu {0=OnOff1_Off, 1=OnOff1_On; unit Unitless}, "The signal informs if Cruise Controller can be activated or not. Primarily used by HMI to know if Cruise Controller activation requests by driver should be ignored or not."}, init-value=constant-reference=CrsCtrlrActvnOk_3}, required-interface=CrsCtrlrActvnOk_3
      CllsnMtgtnFctSts: nonqueued-receiver-com-spec{data-element=CllsnMtgtnFctSts, network-representation={base-type=CllsnMtgtnFctSts_2, compu-method=CllsnMtgtnFctSts_2, "Shows if the AEB function is on or off."}, init-value=constant-reference=CllsnMtgtnFctSts_4}, required-interface=CllsnMtgtnFctSts_4
      BrkTracCtrlActv: nonqueued-receiver-com-spec{data-element=BrkTracCtrlActv, network-representation={base-type=CtrlSts1_2, compu {0=CtrlSts1_NoCtrl, 1=CtrlSts1_InCtrl; unit Unitless}, "Indicates InCtrl if brake traction control (TC) is active on at least one wheel."}, init-value=constant-reference=BrkTracCtrlActv_7}, required-interface=BrkTracCtrlActv_7
      CllsnAidPost: nonqueued-receiver-com-spec{data-element=CllsnAidPost, network-representation={base-type=OnOff1_2, compu {0=OnOff1_Off, 1=OnOff1_On; unit Unitless}, "indicate the AEB brake intervention to the driver."}, init-value=constant-reference=CllsnAidPost_2}, required-interface=CllsnAidPost_2
      EpbSts: nonqueued-receiver-com-spec{composite-network-representations=[{leaf-element=EpbSts.EpbSts, network-representation={base-type=EpbSts_2, compu-method=EpbSts_1, "Electrical Park Brake system status information Status for the rear wheel park actuator"}}, {leaf-element=EpbSts.EpbStsChks, network-representation={base-type=UInt8_2, compu {identical; unit Unitless}, "Electrical Park Brake system status information Status for the rear wheel park actuator"}}, {leaf-element=EpbSts.EpbStsCntr, network-representation={base-type=UInt4_2, compu {identical; unit Unitless}, "Electrical Park Brake system status information Counter for EPB status"}}], data-element=EpbSts, init-value=constant-reference=EpbSts_5}, required-interface=EpbSts_5
      RlyPwrDistbnCmd1WdIgnRlyExtCmd: nonqueued-receiver-com-spec{data-element=RlyPwrDistbnCmd1WdIgnRlyExtCmd, network-representation={base-type=OnOff1_2, compu {0=OnOff1_Off, 1=OnOff1_On; unit Unitless}, "status of the ignition extended relay"}, init-value=constant-reference=RlyPwrDistbnCmd1WdIgnRlyExtCmd_6}, required-interface=RlyPwrDistbnCmd1WdIgnRlyExtCmd_6
      DrvrSeatPosPerc: nonqueued-receiver-com-spec{composite-network-representations=[{leaf-element=DrvrSeatPosPerc.SeatPosSldQF, network-representation={base-type=Qf1_2, compu-method=Qf1_1, "Length Position Quality Factor"}}, {leaf-element=DrvrSeatPosPerc.SeatPosSldPerc, network-representation={base-type=Perc9_2, compu {phys=raw*0.1 for raw 0..1000; unit %}, "Length Position Percentage"}}, {leaf-element=DrvrSeatPosPerc.SeatPosHeiQF, network-representation={base-type=Qf1_2, compu-method=Qf1_1, "Height Position Quality Factor"}}, {leaf-element=DrvrSeatPosPerc.SeatPosHeiPerc, network-representation={base-type=Perc9_2, compu {phys=raw*0.1 for raw 0..1000; unit %}, "Height Position Percentage"}}, {leaf-element=DrvrSeatPosPerc.SeatPosFrntHeiQF, network-representation={base-type=Qf1_2, compu-method=Qf1_1, "Front Height Position Quality Factor"}}, {leaf-element=DrvrSeatPosPerc.SeatPosFrntHeiPerc, network-representation={base-type=Perc9_2, compu {phys=raw*0.1 for raw 0..1000; unit %}, "Front Height Position Percentage"}}], data-element=DrvrSeatPosPerc, init-value=constant-reference=DrvrSeatPosPerc_4}, required-interface=DrvrSeatPosPerc_4
      PassSeatPosPerc: nonqueued-receiver-com-spec{composite-network-representations=[{leaf-element=PassSeatPosPerc.SeatPosSldQF, network-representation={base-type=Qf1_2, compu-method=Qf1_1, "Length Position Quality Factor"}}, {leaf-element=PassSeatPosPerc.SeatPosSldPerc, network-representation={base-type=Perc9_2, compu {phys=raw*0.1 for raw 0..1000; unit %}, "Length Position Percentage"}}, {leaf-element=PassSeatPosPerc.SeatPosHeiQF, network-representation={base-type=Qf1_2, compu-method=Qf1_1, "Height Position Quality Factor"}}, {leaf-element=PassSeatPosPerc.SeatPosHeiPerc, network-representation={base-type=Perc9_2, compu {phys=raw*0.1 for raw 0..1000; unit %}, "Height Position Percentage"}}, {leaf-element=PassSeatPosPerc.SeatPosFrntHeiQF, network-representation={base-type=Qf1_2, compu-method=Qf1_1, "Front Height Position Quality Factor"}}, {leaf-element=PassSeatPosPerc.SeatPosFrntHeiPerc, network-representation={base-type=Perc9_2, compu {phys=raw*0.1 for raw 0..1000; unit %}, "Front Height Position Percentage"}}], data-element=PassSeatPosPerc, init-value=constant-reference=PassSeatPosPerc_4}, required-interface=PassSeatPosPerc_4
      PinionSteerAgGroup: nonqueued-receiver-com-spec{composite-network-representations=[{leaf-element=PinionSteerAgGroup.PinionSteerAg1, network-representation={base-type=Ag4_2, compu {phys=raw/1024 for raw -14848..14848; unit rad}, "Calculated pinion steer angle at the front steering device"}}, {leaf-element=PinionSteerAgGroup.PinionSteerAg1Qf, network-representation={base-type=GenQf1_2, compu-method=GenQf1_1, "Quality factor for PinionSteerAg1"}}, {leaf-element=PinionSteerAgGroup.PinionSteerAgSpd1, network-representation={base-type=AgSpd1_2, compu {phys=raw/128 for raw -6400..6400; unit rad/s}, "Calculated pinion steer angle speed at the front steering device"}}, {leaf-element=PinionSteerAgGroup.PinionSteerAgSpd1Qf, network-representation={base-type=GenQf1_2, compu-method=GenQf1_1, "Quality factor for PinionSteerAgSpd1"}}, {leaf-element=PinionSteerAgGroup.SteerWhlTq, network-representation={base-type=Tq1_2, compu {phys=raw/256 for raw -7680..7680; unit NewtonMeter}, "Torque on steering wheel"}}, {leaf-element=PinionSteerAgGroup.SteerWhlTqQf, network-representation={base-type=GenQf1_2, compu-method=GenQf1_1, "Quality factor for SteerWhlTq"}}, {leaf-element=PinionSteerAgGroup.Cntr, network-representation={base-type=UInt4_2, compu {identical; unit Unitless}, "Counter for PinionSteerAgGroup"}}, {leaf-element=PinionSteerAgGroup.Chks, network-representation={base-type=UInt8_2, compu {identical; unit Unitless}, "Checksum for PinionSteerAgGroup"}}], data-element=PinionSteerAgGroup, init-value=constant-reference=PinionSteerAgGroup_2}, required-interface=PinionSteerAgGroup_2
      PinionSteerAgMax1: nonqueued-receiver-com-spec{data-element=PinionSteerAgMax1, network-representation={base-type=Ag4_2, compu {phys=raw/1024 for raw -14848..14848; unit rad}, "PinionSteerAgMax1 contains the current maximal pinion angle. Depends on tire size and vehicle type."}, init-value=constant-reference=PinionSteerAgMax1_5}, required-interface=PinionSteerAgMax1_5
      DispOfPrpsnMod: nonqueued-receiver-com-spec{data-element=DispOfPrpsnMod, network-representation={base-type=DispOfPrpsnMod4_3, compu-method=DispOfPrpsnMod4_3, "Description: Actual powertrain propulsion mode of the hybrid propulsion system. Usage: For hybrid power flow status display in HMI."}, init-value=constant-reference=DispOfPrpsnMod_7}, required-interface=DispOfPrpsnMod_7
      EmgyAsscTrigSts: nonqueued-receiver-com-spec{data-element=EmgyAsscTrigSts, network-representation={base-type=AfsStsReq_7, compu-method=AfsStsReq_4, "Defined the signal as: 0: when the eCall without trigget 1: eCall been automatically trigget by SRS 2: eCall been manually trigget by user via SOS button 3: eCall has fault when SRS trigget crash"}, init-value=constant-reference=EmgyAsscTrigSts_2}, required-interface=EmgyAsscTrigSts_2
      IsgSpdActSgn: nonqueued-receiver-com-spec{data-element=IsgSpdActSgn, network-representation={base-type=MotSpd_1, compu {phys=raw-20000 for raw 0..65535; unit rpm}, "Actual ISG speed with sign to indicate forward or backward direction"}, init-value=constant-reference=IsgSpdActSgn_8}, required-interface=IsgSpdActSgn_8
      TiAndDateIndcn: nonqueued-receiver-com-spec{composite-network-representations=[{leaf-element=TiAndDateIndcn.Yr1, network-representation={base-type=Yr1_2, compu {identical; unit Year}, "Current time (Hr, Min and Sec) and date (Year, Months and days) data for indication. See requirement for more information about the signals. Year, 0-99"}}, {leaf-element=TiAndDateIndcn.Mth1, network-representation={base-type=Mth1_2, compu {identical; unit Month}, "Current time (Hr, Min and Sec) and date (Year, Months and days) data for indication. See requirement for more information about the signals. Month, 1-12"}}, {leaf-element=TiAndDateIndcn.Day, network-representation={base-type=Day1_2, compu {identical; unit Days}, "Current time (Hr, Min and Sec) and date (Year, Months and days) data for indication. See requirement for more information about the signals. Day"}}, {leaf-element=TiAndDateIndcn.Hr1, network-representation={base-type=Hr1_2, compu {identical; unit hours}, "Current time (Hr, Min and Sec) and date (Year, Months and days) data for indication. See requirement for more information about the signals. Hour"}}, {leaf-element=TiAndDateIndcn.Mins1, network-representation={base-type=Mins1_2, compu {identical; unit Mins}, "Current time (Hr, Min and Sec) and date (Year, Months and days) data for indication. See requirement for more information about the signals. Minutes"}}, {leaf-element=TiAndDateIndcn.Sec1, network-representation={base-type=Sec1_2, compu {identical; unit s}, "Current time (Hr, Min and Sec) and date (Year, Months and days) data for indication. See requirement for more information about the signals. Seconds"}}, {leaf-element=TiAndDateIndcn.DataValid, network-representation={base-type=NoYes1_2, compu {0=NoYes1_No, 1=NoYes1_Yes; unit Unitless}, "Current time (Hr, Min and Sec) and date (Year, Months and days) data for indication. See requirement for more information about the signals. Signal qualifier, No means values should be ignored."}}], data-element=TiAndDateIndcn, init-value=constant-reference=TiAndDateIndcn_5}, required-interface=TiAndDateIndcn_5
      SwtLiHzrdWarn: nonqueued-receiver-com-spec{data-element=SwtLiHzrdWarn, network-representation={base-type=PsdNotPsd_2, compu {0=PsdNotPsd_NotPsd, 1=PsdNotPsd_Psd; unit Unitless}, "Hazard warning light switch signal. 0-not pressed, 1-pressed"}, init-value=constant-reference=SwtLiHzrdWarn_2}, required-interface=SwtLiHzrdWarn_2
      SwtIndcr: nonqueued-receiver-com-spec{composite-network-representations=[{leaf-element=SwtIndcr.IndcrTypExtReq, network-representation={base-type=IndcrTypExt1_2, compu-method=IndcrTypExt1_1, "Signal represent status of the turn stalk swich"}}, {leaf-element=SwtIndcr.IndcrTypExtReqToUpdQf, network-representation={base-type=Qf1_2, compu-method=Qf1_1, "Qf"}}, {leaf-element=SwtIndcr.IndcrTypExtReqCntr, network-representation={base-type=UInt2_2, compu {identical; unit Unitless}, "Counter"}}, {leaf-element=SwtIndcr.IndcrTypExtReqChks, network-representation={base-type=UInt8_2, compu {identical; unit Unitless}, "Checksum"}}], data-element=SwtIndcr, init-value=constant-reference=SwtIndcr_4}, required-interface=SwtIndcr_4
      CllsnFwdWarn: nonqueued-receiver-com-spec{data-element=CllsnFwdWarn, network-representation={base-type=CllsnFwdWarnReq_1, compu-method=CllsnFwdWarnReq_1, "indicate the FCW warning and Latent warning activation."}, init-value=constant-reference=CllsnFwdWarn_2}, required-interface=CllsnFwdWarn_2
      BrkPedlrRat: nonqueued-receiver-com-spec{composite-network-representations=[{leaf-element=BrkPedlrRat.BrkPedlrRatPerc, network-representation={base-type=Perc1_2, compu {phys=raw/256 for raw 0..25600; unit %}, "Brake pedal Ratio in percentage value"}}, {leaf-element=BrkPedlrRat.BrkPedlrRatQf, network-representation={base-type=GenQf1_2, compu-method=GenQf1_1, "quality factor"}}], data-element=BrkPedlrRat, init-value=constant-reference=BrkPedlrRat_5}, required-interface=BrkPedlrRat_5
      SftyDecelGroupSafe: nonqueued-receiver-com-spec{composite-network-representations=[{leaf-element=SftyDecelGroupSafe.AsySftyEnaDecel, network-representation={base-type=OnOff1_2, compu {0=OnOff1_Off, 1=OnOff1_On; unit Unitless}, "brake order"}}, {leaf-element=SftyDecelGroupSafe.SftyDecelGroupSafeChks, network-representation={base-type=UInt8_2, compu {identical; unit Unitless}, "crc"}}, {leaf-element=SftyDecelGroupSafe.SftyDecelGroupSafeCntr, network-representation={base-type=UInt4_2, compu {identical; unit Unitless}, "counter"}}, {leaf-element=SftyDecelGroupSafe.AsySftyDecelReq, network-representation={base-type=Decel_1, compu {phys=raw*0.1 for raw 0..150; unit m/s^2}, "target deceleration"}}], data-element=SftyDecelGroupSafe, init-value=constant-reference=SftyDecelGroupSafe_5a1}, required-interface=SftyDecelGroupSafe_5a1
      ActvnStsOfRtrctrRvsbLe: nonqueued-receiver-com-spec{data-element=ActvnStsOfRtrctrRvsbLe, network-representation={base-type=Enumeration1_2, compu {0=Enumeration1_NotActvd, 1=Enumeration1_Actvd; unit Unitless}, "Signals to the SRS (and other nodes) that the belts have triggered."}, init-value=constant-reference=ActvnStsOfRtrctrRvsbLe_5}, required-interface=ActvnStsOfRtrctrRvsbLe_5
      PreCrashFrontData: nonqueued-receiver-com-spec{composite-network-representations=[{leaf-element=PreCrashFrontData.Chks, network-representation={base-type=UInt8_2, compu {identical; unit Unitless}, "crc"}}, {leaf-element=PreCrashFrontData.Cntr, network-representation={base-type=UInt4_2, compu {identical; unit Unitless}, "counter"}}, {leaf-element=PreCrashFrontData.TimeToImpact, network-representation={base-type=TimeToImpact_1, compu {phys=raw*0.004 for raw 0..255; unit s}, "time to impact"}}, {leaf-element=PreCrashFrontData.ObjectClass, network-representation={base-type=ObjectClass_2, compu-method=ObjectClass_2, "object type"}}, {leaf-element=PreCrashFrontData.ClosingVelocity, network-representation={base-type=ClosingVelocity_1, compu {phys=raw*0.167 for raw 0..255; unit m/s}, "collision relative velocity"}}, {leaf-element=PreCrashFrontData.OverLap, network-representation={base-type=PercSign1_2, compu {phys=raw-100 for raw 0..200; unit %}, "overlap"}}], data-element=PreCrashFrontData, uses-end-to-end-protection=true, init-value=constant-reference=PreCrashFrontData_5}, required-interface=PreCrashFrontData_5
      StsForRtrctrRvsbLe: nonqueued-receiver-com-spec{data-element=StsForRtrctrRvsbLe, network-representation={base-type=NotOkOk_2, compu-method=NotOkOk_2, "Belt ready status"}, init-value=constant-reference=StsForRtrctrRvsbLe_5}, required-interface=StsForRtrctrRvsbLe_5
      VehHomePrkgSysSts: nonqueued-receiver-com-spec{data-element=VehHomePrkgSysSts, network-representation={base-type=HomePrkgSysSts1_2, compu-method=HomePrkgSysSts1_2, "Home zone parking system status."}, init-value=constant-reference=VehHomePrkgSysSts_4}, required-interface=VehHomePrkgSysSts_4
      Overlap: nonqueued-receiver-com-spec{data-element=Overlap, network-representation={base-type=PercSign1_2, compu {phys=raw-100 for raw 0..200; unit %}, "predicted Object Overlap, i.e. the portion of the ego vehicle covered by the collision object, is between 25% and 100%."}, init-value=constant-reference=Overlap_1}, required-interface=Overlap_1
      VehSpdIndcd: nonqueued-receiver-com-spec{composite-network-representations=[{leaf-element=VehSpdIndcd.VehSpdIndcd, network-representation={base-type=Nr32_2, compu {identical; unit Unitless}, "Vehicle speed"}}, {leaf-element=VehSpdIndcd.VeSpdIndcdUnit, network-representation={base-type=VehSpdIndcdUnit_2, compu-method=VehSpdIndcdUnit_1, "Unit for vehicle speed"}}], data-element=VehSpdIndcd, init-value=constant-reference=VehSpdIndcd_3}, required-interface=VehSpdIndcd_3
      SRSdevelpsignalgroupRX: nonqueued-receiver-com-spec{composite-network-representations=[{leaf-element=SRSdevelpsignalgroupRX.Functiondevpsignalgroup1, network-representation={base-type=UInt8_2, compu {identical; unit Unitless}, "SRS development signal"}}, {leaf-element=SRSdevelpsignalgroupRX.Functiondevpsignalgroup2, network-representation={base-type=UInt8_2, compu {identical; unit Unitless}, "SRS development signal"}}, {leaf-element=SRSdevelpsignalgroupRX.Functiondevpsignalgroup3, network-representation={base-type=UInt8_2, compu {identical; unit Unitless}, "SRS development signal"}}, {leaf-element=SRSdevelpsignalgroupRX.Functiondevpsignalgroup4, network-representation={base-type=UInt8_2, compu {identical; unit Unitless}, "SRS development signal"}}, {leaf-element=SRSdevelpsignalgroupRX.Functiondevpsignalgroup5, network-representation={base-type=UInt8_2, compu {identical; unit Unitless}, "SRS development signal"}}, {leaf-element=SRSdevelpsignalgroupRX.Functiondevpsignalgroup6, network-representation={base-type=UInt8_2, compu {identical; unit Unitless}, "SRS development signal"}}, {leaf-element=SRSdevelpsignalgroupRX.Functiondevpsignalgroup7, network-representation={base-type=UInt8_2, compu {identical; unit Unitless}, "SRS development signal"}}, {leaf-element=SRSdevelpsignalgroupRX.Functiondevpsignalgroup8, network-representation={base-type=UInt8_2, compu {identical; unit Unitless}, "SRS development signal"}}], data-element=SRSdevelpsignalgroupRX, init-value=constant-reference=SRSdevelpsignalgroupRX_3}, required-interface=SRSdevelpsignalgroupRX_3
      PrkgStsToEDR: nonqueued-receiver-com-spec{composite-network-representations=[{leaf-element=PrkgStsToEDR.APATo, network-representation={base-type=APATo_1, compu-method=APATo_1, "APATo"}}, {leaf-element=PrkgStsToEDR.RPATo, network-representation={base-type=APATo_1, compu-method=APATo_1, "RPATo"}}, {leaf-element=PrkgStsToEDR.HPATo, network-representation={base-type=APATo_1, compu-method=APATo_1, "HPATo"}}, {leaf-element=PrkgStsToEDR.LSDAandTBATo, network-representation={base-type=APATo_1, compu-method=APATo_1, "LSDA&&TBATo"}}, {leaf-element=PrkgStsToEDR.reserved1, network-representation={base-type=APATo_1, compu-method=APATo_1, "reserved1"}}, {leaf-element=PrkgStsToEDR.reserved2, network-representation={base-type=APATo_1, compu-method=APATo_1, "reserved2"}}, {leaf-element=PrkgStsToEDR.reserved3, network-representation={base-type=APATo_1, compu-method=APATo_1, "reserved3"}}], data-element=PrkgStsToEDR, init-value=constant-reference=PrkgStsToEDR_1}, required-interface=PrkgStsToEDR_1
      AsySftyFctStsToEDR: nonqueued-receiver-com-spec{composite-network-representations=[{leaf-element=AsySftyFctStsToEDR.AEBSFctSts, network-representation={base-type=AEBSFctSts_1, compu-method=AEBSFctSts_1, "The signal indicates the function status of the AEB and FCW function."}}, {leaf-element=AsySftyFctStsToEDR.ACCFctSTs, network-representation={base-type=FctSTs_1, compu-method=ACCFctSTs_1, "The signal indicates the function status of the ACC function."}}, {leaf-element=AsySftyFctStsToEDR.LDWSFctSts, network-representation={base-type=LDWSFctSts_1, compu-method=LDWSFctSts_1, "The signal indicates the function status of the LDW function."}}, {leaf-element=AsySftyFctStsToEDR.CSFFctSts, network-representation={base-type=FctSTs_1, compu-method=ACCFctSTs_1, "The signal indicates the function status of the LKA function."}}, {leaf-element=AsySftyFctStsToEDR.ESFFctSts, network-representation={base-type=FctSTs_1, compu-method=ACCFctSTs_1, "The signal indicates the function status of the ELKA function."}}, {leaf-element=AsySftyFctStsToEDR.ACSFB1FctSts, network-representation={base-type=FctSTs_1, compu-method=ACCFctSTs_1, "The signal indicates the function status of the HWA function."}}, {leaf-element=AsySftyFctStsToEDR.ACSFB2FctSts, network-representation={base-type=FctSTs_1, compu-method=ACCFctSTs_1, "The signal indicates the function status of the ACSF B2."}}, {leaf-element=AsySftyFctStsToEDR.ACSFCFctSts, network-representation={base-type=FctSTs_1, compu-method=ACCFctSTs_1, "The signal indicates the function status of the ALCA function."}}, {leaf-element=AsySftyFctStsToEDR.ACSFDFctSts, network-representation={base-type=FctSTs_1, compu-method=ACCFctSTs_1, "The signal indicates the function status of the ACSF D."}}, {leaf-element=AsySftyFctStsToEDR.ACSFEFctSts, network-representation={base-type=FctSTs_1, compu-method=ACCFctSTs_1, "The signal indicates the function status of the ACSF E."}}], data-element=AsySftyFctStsToEDR, init-value=constant-reference=AsySftyFctStsToEDR_1}, required-interface=AsySftyFctStsToEDR_1
      WhlMotSysSpdAct: nonqueued-receiver-com-spec{data-element=WhlMotSysSpdAct, network-representation={base-type=MotSpd_1, compu {phys=raw-20000 for raw 0..65535; unit rpm}, "The actual rotational speed of rear motor"}, init-value=constant-reference=WhlMotSysSpdAct_5}, required-interface=WhlMotSysSpdAct_5
      VehCfgPrmExt2: nonqueued-receiver-com-spec{composite-network-representations=[{leaf-element=VehCfgPrmExt2.BlkIDBytePosn1, network-representation={base-type=Nr2_3, compu {phys=raw for raw 0..255; unit Unitless}, "CarConfigExtended2 BlockID"}}, {leaf-element=VehCfgPrmExt2.CCPBytePosn2, network-representation={base-type=Nr2_3, compu {phys=raw for raw 0..255; unit Unitless}, "CarConfigExtended2 BytePos2"}}, {leaf-element=VehCfgPrmExt2.CCPBytePosn3, network-representation={base-type=Nr2_3, compu {phys=raw for raw 0..255; unit Unitless}, "CarConfigExtended2 BytePos3"}}, {leaf-element=VehCfgPrmExt2.CCPBytePosn4, network-representation={base-type=Nr2_3, compu {phys=raw for raw 0..255; unit Unitless}, "CarConfigExtended2 BytePos4"}}, {leaf-element=VehCfgPrmExt2.CCPBytePosn5, network-representation={base-type=Nr2_3, compu {phys=raw for raw 0..255; unit Unitless}, "CarConfigExtended2 BytePos5"}}, {leaf-element=VehCfgPrmExt2.CCPBytePosn6, network-representation={base-type=Nr2_3, compu {phys=raw for raw 0..255; unit Unitless}, "CarConfigExtended2 BytePos6"}}, {leaf-element=VehCfgPrmExt2.CCPBytePosn7, network-representation={base-type=Nr2_3, compu {phys=raw for raw 0..255; unit Unitless}, "CarConfigExtended2 BytePos7"}}, {leaf-element=VehCfgPrmExt2.CCPBytePosn8, network-representation={base-type=Nr2_3, compu {phys=raw for raw 0..255; unit Unitless}, "CarConfigExtended2 BytePos8"}}], data-element=VehCfgPrmExt2, init-value=constant-reference=VehCfgPrmExt2_1}, required-interface=VehCfgPrmExt2_1
      ZCUDMResdSig1ToSRSSafety: nonqueued-receiver-com-spec{composite-network-representations=[{leaf-element=ZCUDMResdSig1ToSRSSafety.Chks, network-representation={base-type=UInt8_2, compu {identical; unit Unitless}, "ZCUDMResdSig1ToSRSSafety"}}, {leaf-element=ZCUDMResdSig1ToSRSSafety.Cntr, network-representation={base-type=UInt4_2, compu {identical; unit Unitless}, "ZCUDMResdSig1ToSRSSafety"}}, {leaf-element=ZCUDMResdSig1ToSRSSafety.UInt32, network-representation={base-type=UInt32_2, compu {identical; unit Unitless}, "ZCUDMResdSig1ToSRSSafety"}}], data-element=ZCUDMResdSig1ToSRSSafety, init-value=constant-reference=ZCUDMResdSig1ToSRSSafety_1}, required-interface=ZCUDMResdSig1ToSRSSafety_1
      ActvnStsOfRtrctrRvsbRi: nonqueued-receiver-com-spec{data-element=ActvnStsOfRtrctrRvsbRi, network-representation={base-type=Enumeration1_2, compu {0=Enumeration1_NotActvd, 1=Enumeration1_Actvd; unit Unitless}, "Signals to the SRS (and other nodes) that the belts have triggered."}, init-value=constant-reference=ActvnStsOfRtrctrRvsbRi_6}, required-interface=ActvnStsOfRtrctrRvsbRi_6
      StsForRtrctrRvsbRi: nonqueued-receiver-com-spec{data-element=StsForRtrctrRvsbRi, network-representation={base-type=NotOkOk_2, compu-method=NotOkOk_2, "Belt ready status"}, init-value=constant-reference=StsForRtrctrRvsbRi_6}, required-interface=StsForRtrctrRvsbRi_6
      WhlSpdCircumlRe: nonqueued-receiver-com-spec{composite-network-representations=[{leaf-element=WhlSpdCircumlRe.WhlSpdCircumlReLe, network-representation={base-type=Spd1_2, compu {phys=raw*0.00391 for raw 0..31970; unit m/s}, "Individual wheel speed from rear wheel speed sensors. Wheel speed from rear left wheel speed sensor using nominal value of wheel radius."}}, {leaf-element=WhlSpdCircumlRe.WhlSpdCircumlReLeQf, network-representation={base-type=GenQf1_2, compu-method=GenQf1_1, "Individual wheel speed from rear wheel speed sensors. Qf for wheel speed sensor"}}, {leaf-element=WhlSpdCircumlRe.WhlSpdCircumlReRi, network-representation={base-type=Spd1_2, compu {phys=raw*0.00391 for raw 0..31970; unit m/s}, "Individual wheel speed from rear wheel speed sensors. Wheel speed from rear right wheel speed sensor using nominal value of wheel radius."}}, {leaf-element=WhlSpdCircumlRe.WhlSpdCircumlReRiQf, network-representation={base-type=GenQf1_2, compu-method=GenQf1_1, "Individual wheel speed from rear wheel speed sensors. Qf for wheel speed sensor"}}, {leaf-element=WhlSpdCircumlRe.WhlSpdCircumlReChks, network-representation={base-type=UInt8_2, compu {identical; unit Unitless}, "Individual wheel speed from rear wheel speed sensors. Checksum"}}, {leaf-element=WhlSpdCircumlRe.WhlSpdCircumlReCntr, network-representation={base-type=UInt4_2, compu {identical; unit Unitless}, "Individual wheel speed from rear wheel speed sensors. Counter"}}], data-element=WhlSpdCircumlRe, init-value=constant-reference=WhlSpdCircumlRe_9}, required-interface=WhlSpdCircumlRe_9
      WhlSpdCircumlFrnt: nonqueued-receiver-com-spec{composite-network-representations=[{leaf-element=WhlSpdCircumlFrnt.WhlSpdCircumlFrntLe, network-representation={base-type=Spd1_2, compu {phys=raw*0.00391 for raw 0..31970; unit m/s}, "Individual wheel speed from front wheel speed sensors. Wheel speed from front left wheel speed sensor using nominal value of wheel radius."}}, {leaf-element=WhlSpdCircumlFrnt.WhlSpdCircumlFrntLeQf, network-representation={base-type=GenQf1_2, compu-method=GenQf1_1, "Individual wheel speed from front wheel speed sensors. Qf for wheel speed sensor"}}, {leaf-element=WhlSpdCircumlFrnt.WhlSpdCircumlFrntWhlSpdCircumlFrntRi, network-representation={base-type=Spd1_2, compu {phys=raw*0.00391 for raw 0..31970; unit m/s}, "Individual wheel speed from front wheel speed sensors. Wheel speed from front right wheel speed sensor using nominal value of wheel radius"}}, {leaf-element=WhlSpdCircumlFrnt.WhlSpdCircumlFrntRiQf, network-representation={base-type=GenQf1_2, compu-method=GenQf1_1, "Individual wheel speed from front wheel speed sensors. Qf for wheel speed sensor"}}, {leaf-element=WhlSpdCircumlFrnt.WhlSpdCircumlFrntChks, network-representation={base-type=UInt8_2, compu {identical; unit Unitless}, "Individual wheel speed from front wheel speed sensors. Checksum"}}, {leaf-element=WhlSpdCircumlFrnt.WhlSpdCircumlFrntCntr, network-representation={base-type=UInt4_2, compu {identical; unit Unitless}, "Individual wheel speed from front wheel speed sensors. Counter"}}], data-element=WhlSpdCircumlFrnt, init-value=constant-reference=WhlSpdCircumlFrnt_10}, required-interface=WhlSpdCircumlFrnt_10
      SftyAirbRollovrSuppSwt: nonqueued-receiver-com-spec{data-element=SftyAirbRollovrSuppSwt, network-representation={base-type=OnOffNoReq_2, compu {0=OnOffNoReq_NoReq, 1=OnOffNoReq_On, 2=OnOffNoReq_Off; unit Unitless}, "Aigbag roll over deactivate switch request"}, init-value=constant-reference=SftyAirbRollovrSuppSwt_1}, required-interface=SftyAirbRollovrSuppSwt_1
      SumActv: nonqueued-receiver-com-spec{data-element=SumActv, network-representation={base-type=Boolean_2, compu {0=Boolean_FALSE, 1=Boolean_TRUE; unit Unitless}, "VMM force all the ECUs into sleep mode during abandon. SUM must inform VMM if it is still running."}, init-value=constant-reference=SumActv_5}, required-interface=SumActv_5
      WhlDirRotlRe: nonqueued-receiver-com-spec{composite-network-representations=[{leaf-element=WhlDirRotlRe.Le, network-representation={base-type=WhlRotlDirStd1_2, compu-method=WhlRotlDirStd1_1, "Rotational direction for the rear individual wheels. Wheel rotation direction of rear left wheel."}}, {leaf-element=WhlDirRotlRe.Ri, network-representation={base-type=WhlRotlDirStd1_2, compu-method=WhlRotlDirStd1_1, "Rotational direction for the rear individual wheels. Wheel rotation direction of rear right wheel."}}, {leaf-element=WhlDirRotlRe.Chks, network-representation={base-type=UInt8_2, compu {identical; unit Unitless}, "checksum"}}, {leaf-element=WhlDirRotlRe.Cntr, network-representation={base-type=UInt4_2, compu {identical; unit Unitless}, "counter"}}], data-element=WhlDirRotlRe, init-value=constant-reference=WhlDirRotlRe_9}, required-interface=WhlDirRotlRe_9
      WhlDirRotlFrnt: nonqueued-receiver-com-spec{composite-network-representations=[{leaf-element=WhlDirRotlFrnt.Le, network-representation={base-type=WhlRotlDirStd1_2, compu-method=WhlRotlDirStd1_1, "Rotational direction for the front individual wheels. Wheel rotation direction of front left wheel."}}, {leaf-element=WhlDirRotlFrnt.Ri, network-representation={base-type=WhlRotlDirStd1_2, compu-method=WhlRotlDirStd1_1, "Rotational direction for the front individual wheels. Wheel rotation direction of front right wheel."}}, {leaf-element=WhlDirRotlFrnt.Chks, network-representation={base-type=UInt8_2, compu {identical; unit Unitless}, "check sum"}}, {leaf-element=WhlDirRotlFrnt.Cntr, network-representation={base-type=UInt4_2, compu {identical; unit Unitless}, "counter"}}], data-element=WhlDirRotlFrnt, init-value=constant-reference=WhlDirRotlFrnt_3}, required-interface=WhlDirRotlFrnt_3
      EfuseKL15Req{1..5}: nonqueued-receiver-com-spec{data-element=EfuseKL15Req{1..5}, network-representation={base-type=OnOff1_2, compu {0=OnOff1_Off, 1=OnOff1_On; unit Unitless}, "ON/OFF"}, init-value=constant-reference=EfuseKL15Req{1..5}_1}, required-interface=EfuseKL15Req{1..5}_1
      CrsCtrlrMsg: nonqueued-receiver-com-spec{data-element=CrsCtrlrMsg, network-representation={base-type=CrsCtrlrMsg1_2, compu-method=CrsCtrlrMsg1_1, "The signal triggers visual messages in DIM to inform the driver relevant information about the Cruise Controller"}, init-value=constant-reference=CrsCtrlrMsg_2}, required-interface=CrsCtrlrMsg_2
      TurnIndcrAndHwlByDrvInt: nonqueued-receiver-com-spec{data-element=TurnIndcrAndHwlByDrvInt, network-representation={base-type=IndcrSts1_2, compu-method=IndcrSts1_1, "Combine turn switch signals and hazard lights signal"}, init-value=constant-reference=TurnIndcrAndHwlByDrvInt_1}, required-interface=TurnIndcrAndHwlByDrvInt_1
      PassAirbNotiConfirm: nonqueued-receiver-com-spec{data-element=PassAirbNotiConfirm, network-representation={base-type=Onoff3_1, compu {0=Onoff2_Idle, 1=Onoff2_On, 2=Onoff2_On1, 3=Onoff2_Off; unit Unitless}, "Passenger airbag message confirmation feedback"}, init-value=constant-reference=PassAirbNotiConfirm_1}, required-interface=PassAirbNotiConfirm_1
      PassStuMonSts: nonqueued-receiver-com-spec{data-element=PassStuMonSts, network-representation={base-type=UInt4_2, compu {identical; unit Unitless}, "Front passenger body position detection and front and back child seat detection"}, init-value=constant-reference=PassStuMonSts_1}, required-interface=PassStuMonSts_1
      DrvrStuMonSts: nonqueued-receiver-com-spec{data-element=DrvrStuMonSts, network-representation={base-type=UInt4_2, compu {identical; unit Unitless}, "Driver's body position detection"}, init-value=constant-reference=DrvrStuMonSts_1}, required-interface=DrvrStuMonSts_1
      BrkTqAtWhlsReq: nonqueued-receiver-com-spec{data-element=BrkTqAtWhlsReq, network-representation={base-type=Tq32_2, compu {phys=raw*4 for raw 0..4095; unit Nm}, "Contains driver requested brake torque and driver support system requested brake torque. The signal is always positive and acts in opposite vehicle motion direction."}, init-value=constant-reference=BrkTqAtWhlsReq_6}, required-interface=BrkTqAtWhlsReq_6
      HoodSts: nonqueued-receiver-com-spec{data-element=HoodSts, network-representation={base-type=DoorSts2_2, compu {0=DoorSts2_Ukwn, 1=DoorSts2_Opend, 2=DoorSts2_Clsd; unit Unitless}, "HoodSts - Hood Status Ukwn - Unknown status Opend - Opened Clsd - Closed"}, init-value=constant-reference=HoodSts_5}, required-interface=HoodSts_5
      EngNSafe: nonqueued-receiver-com-spec{composite-network-representations=[{leaf-element=EngNSafe.EngN, network-representation={base-type=N30_2, compu {phys=raw*0.5 for raw 0..32767; unit rpm}, "Engine Speed [rpm] and Engine Speed derivative [rpm/s]"}}, {leaf-element=EngNSafe.EngNGrdt, network-representation={base-type=NGrdt1_2, compu {phys=raw for raw -30000..32767; unit RpmPerSec}, "Engine Speed [rpm] and Engine Speed derivative [rpm/s]"}}, {leaf-element=EngNSafe.EngNChks, network-representation={base-type=UInt8_2, compu {identical; unit Unitless}, "Engine Speed [rpm] and Engine Speed derivative [rpm/s]"}}, {leaf-element=EngNSafe.EngNCntr, network-representation={base-type=UInt4_2, compu {identical; unit Unitless}, "Engine Speed [rpm] and Engine Speed derivative [rpm/s]"}}], data-element=EngNSafe, init-value=constant-reference=EngNSafe_7}, required-interface=EngNSafe_7
      BrkFricTqTotAtWhlsAct: nonqueued-receiver-com-spec{composite-network-representations=[{leaf-element=BrkFricTqTotAtWhlsAct.BrkFricTqTotAtWhlsAct, network-representation={base-type=Tq10_2, compu {phys=raw for raw 0..20000; unit NewtonMeter}, "Total actual friction brake toque at all four wheels."}}, {leaf-element=BrkFricTqTotAtWhlsAct.BrkFricTqTotAtWhlsActChks, network-representation={base-type=UInt8_2, compu {identical; unit Unitless}, "Total actual friction brake toque at all four wheels. Checksum"}}, {leaf-element=BrkFricTqTotAtWhlsAct.BrkFricTqTotAtWhlsActCntr, network-representation={base-type=UInt4_2, compu {identical; unit Unitless}, "Total actual friction brake toque at all four wheels. Counter"}}], data-element=BrkFricTqTotAtWhlsAct, init-value=constant-reference=BrkFricTqTotAtWhlsAct_8}, required-interface=BrkFricTqTotAtWhlsAct_8
    8 x port group, all with category=PARTIAL_NETWORKING:
      Diagnostics
        outer-ports:
          RecOfPostImpctBrkgCfmd
          RecOfPostImpctBrkgSuspc
          BrkPedlSts
          CrashSts2
          NotifForEmgyCall
          RestrntSysLampReq
          RestrntSysMsgReq
          BltLockStAtDrvr
          BltLockStAtRowSecLe
          BltLockStAtRowSecMid
          BltLockStAtRowSecRi
          BltLockStAtRowThrdLe
          BltLockStAtRowThrdRi
          BltLockStSafeAtDrvr
          PassAirbLampReq
          RecOfImpct
          PedProtnMsgReqForImpct
          PedProtnMsgReqForFlt
          BltLockStAtPass
          SafetyCrashFb
          CrashStsSafe
          BltLockStAtRowThrdMid
          SeatOccptAtRowThrdMid
          BltLockStAtPassMid
          BltLockStAtRowFrthLe
          BltLockStAtRowFrthMid
          BltLockStAtRowFrthRi
          PassMidSeatSts
          SeatOccptAtRowFrthLe
          SeatOccptAtRowFrthMid
          SeatOccptAtRowFrthRi
          RecOfImpct2
          ReqForHzrdInt
          DstTrvldFromSftyBkp
          DstTrvldVldFromSftyBkp
          ActvnReqOfRtrctrRvsbLe
          ActvnReqOfRtrctrRvsbRi
          BltCrashNotif
          PassAirbSts
          SRSResdSig1ToZCUDMSafety
          HVfault
          SRSIntVolt
          SftyAirbRollovrSuppSts
          ReqForAsyDataStorgFromRestrntSys
          PassAirbStsChgNotifReq
          AbsCtrlActv
          CarModCrashSaved
          BrkPedlPsd
          DoorLeReSts
          DoorDrvrSts
          DoorRiReSts
          DoorPassSts
          RlyPwrDistbnCmd1WdIgnRlyCmd
          VehSpdLgt
          PostImpctBrkgRdy
          EscCtrlIndcn
          EscSt
          AmbTIndcdWithUnit
          AccrPedlRat
          ReqForPassAirbIndcnAckd
          ActvnStsOfRtrctrRvsbRi
          ActvnStsOfRtrctrRvsbLe
          StsForRtrctrRvsbLe
          BrkSysCylPMst
          AccrpedlSts
          PassAirbLampStsRec
          VehMtnSt
          EngN2
          ThrPos
          PinionSteerAgMax1
          DrvrSeatPosPerc
          PassSeatPosPerc
          DoorDrvrLockSts
          DoorLeReLockSts
          DoorPassLockSts
          DoorRiReLockSts
          PinionSteerAgGroup
          PreCrashFrontData
          PosnBrief
          AbsSts
          BrkAndAbsWarnIndcnReq
          LeFrntTireMsg
          RiFrntTireMsg
          LeReTireMsg
          RiReTireMsg
          StsForRtrctrRvsbRi
          VehBattU
          AsyALgtSts
          CrsCtrlrSts
          DispOfPrpsnModForEv
          DispOfPrpsnMod
          VehTiAndData
          TrsmActrPosnSafe
          Vin
          GearLvrIndcn
          AsyAutDrvCtrlTyp
          DrvrCrsCtrlFctSeld
          CrsCtrlrStbOk
          CrsCtrlrActvnOk
          BrkTracCtrlActv
          EpbSts
          RlyPwrDistbnCmd1WdIgnRlyExtCmd
          EmgyAsscTrigSts
          IsgSpdActSgn
          WhlMotSysSpdAct
          VehHomePrkgSysSts
          SwtIndcr
          SwtLiHzrdWarn
          BrkPedlrRat
          SftyDecelGroupSafe
          Overlap
          VehSpdIndcd
          PrkgStsToEDR
          AsySftyFctStsToEDR
          CllsnMtgtnFctSts
          CllsnAidPost
          CllsnFwdWarn
          SftyAirbRollovrSuppSwt
          SumActv
          EfuseKL15Req{1..5}
          CrsCtrlrMsg
          PassAirbNotiConfirm
          PassStuMonSts
          DrvrStuMonSts
          TurnIndcrAndHwlByDrvInt
          BkpOfDstTrvld
          ZCUDMResdSig1ToSRSSafety
      VehicleDriving
        outer-ports:
          RecOfPostImpctBrkgCfmd
          RecOfPostImpctBrkgSuspc
          BrkPedlSts
          CrashSts2
          NotifForEmgyCall
          RestrntSysLampReq
          RestrntSysMsgReq
          BltLockStAtDrvr
          BltLockStAtRowSecLe
          BltLockStAtRowSecMid
          BltLockStAtRowSecRi
          BltLockStAtRowThrdLe
          BltLockStAtRowThrdRi
          BltLockStSafeAtDrvr
          PassAirbLampReq
          RecOfImpct
          PedProtnMsgReqForImpct
          PedProtnMsgReqForFlt
          BltLockStAtPass
          SafetyCrashFb
          CrashStsSafe
          BltLockStAtRowThrdMid
          SeatOccptAtRowThrdMid
          BltLockStAtPassMid
          BltLockStAtRowFrthLe
          BltLockStAtRowFrthMid
          BltLockStAtRowFrthRi
          PassMidSeatSts
          SeatOccptAtRowFrthLe
          SeatOccptAtRowFrthMid
          SeatOccptAtRowFrthRi
          RecOfImpct2
          ReqForHzrdInt
          DstTrvldFromSftyBkp
          DstTrvldVldFromSftyBkp
          ActvnReqOfRtrctrRvsbLe
          ActvnReqOfRtrctrRvsbRi
          BltCrashNotif
          PassAirbSts
          SRSResdSig1ToZCUDMSafety
          HVfault
          SRSIntVolt
          SftyAirbRollovrSuppSts
          ReqForAsyDataStorgFromRestrntSys
          PassAirbStsChgNotifReq
          AbsCtrlActv
          CarModCrashSaved
          BrkPedlPsd
          DoorLeReSts
          DoorDrvrSts
          DoorRiReSts
          DoorPassSts
          RlyPwrDistbnCmd1WdIgnRlyCmd
          VehSpdLgt
          PostImpctBrkgRdy
          EscCtrlIndcn
          EscSt
          AmbTIndcdWithUnit
          AccrPedlRat
          ReqForPassAirbIndcnAckd
          ActvnStsOfRtrctrRvsbRi
          ActvnStsOfRtrctrRvsbLe
          StsForRtrctrRvsbLe
          BrkSysCylPMst
          AccrpedlSts
          PassAirbLampStsRec
          VehMtnSt
          EngN2
          ThrPos
          PinionSteerAgMax1
          DrvrSeatPosPerc
          PassSeatPosPerc
          DoorDrvrLockSts
          DoorLeReLockSts
          DoorPassLockSts
          DoorRiReLockSts
          PinionSteerAgGroup
          PreCrashFrontData
          PosnBrief
          AbsSts
          BrkAndAbsWarnIndcnReq
          LeFrntTireMsg
          RiFrntTireMsg
          LeReTireMsg
          RiReTireMsg
          StsForRtrctrRvsbRi
          VehBattU
          AsyALgtSts
          CrsCtrlrSts
          DispOfPrpsnModForEv
          DispOfPrpsnMod
          VehTiAndData
          TrsmActrPosnSafe
          Vin
          GearLvrIndcn
          AsyAutDrvCtrlTyp
          DrvrCrsCtrlFctSeld
          CrsCtrlrStbOk
          CrsCtrlrActvnOk
          BrkTracCtrlActv
          EpbSts
          RlyPwrDistbnCmd1WdIgnRlyExtCmd
          EmgyAsscTrigSts
          IsgSpdActSgn
          WhlMotSysSpdAct
          VehHomePrkgSysSts
          SwtIndcr
          SwtLiHzrdWarn
          BrkPedlrRat
          SftyDecelGroupSafe
          Overlap
          VehSpdIndcd
          PrkgStsToEDR
          AsySftyFctStsToEDR
          CllsnMtgtnFctSts
          CllsnAidPost
          CllsnFwdWarn
          SftyAirbRollovrSuppSwt
          SumActv
          EfuseKL15Req{1..5}
          CrsCtrlrMsg
          PassAirbNotiConfirm
          PassStuMonSts
          DrvrStuMonSts
          TurnIndcrAndHwlByDrvInt
          BkpOfDstTrvld
          ZCUDMResdSig1ToSRSSafety
      VehicleModeManagement
        outer-ports:
          RecOfPostImpctBrkgCfmd
          RecOfPostImpctBrkgSuspc
          BrkPedlSts
          CrashSts2
          NotifForEmgyCall
          RestrntSysLampReq
          RestrntSysMsgReq
          BltLockStAtDrvr
          BltLockStAtRowSecLe
          BltLockStAtRowSecMid
          BltLockStAtRowSecRi
          BltLockStAtRowThrdLe
          BltLockStAtRowThrdRi
          BltLockStSafeAtDrvr
          PassAirbLampReq
          RecOfImpct
          PedProtnMsgReqForImpct
          PedProtnMsgReqForFlt
          BltLockStAtPass
          SafetyCrashFb
          CrashStsSafe
          BltLockStAtRowThrdMid
          SeatOccptAtRowThrdMid
          BltLockStAtPassMid
          BltLockStAtRowFrthLe
          BltLockStAtRowFrthMid
          BltLockStAtRowFrthRi
          PassMidSeatSts
          SeatOccptAtRowFrthLe
          SeatOccptAtRowFrthMid
          SeatOccptAtRowFrthRi
          RecOfImpct2
          ReqForHzrdInt
          DstTrvldFromSftyBkp
          DstTrvldVldFromSftyBkp
          ActvnReqOfRtrctrRvsbLe
          ActvnReqOfRtrctrRvsbRi
          BltCrashNotif
          PassAirbSts
          SRSResdSig1ToZCUDMSafety
          HVfault
          SRSIntVolt
          SftyAirbRollovrSuppSts
          ReqForAsyDataStorgFromRestrntSys
          PassAirbStsChgNotifReq
          AbsCtrlActv
          CarModCrashSaved
          BrkPedlPsd
          DoorLeReSts
          DoorDrvrSts
          DoorRiReSts
          DoorPassSts
          RlyPwrDistbnCmd1WdIgnRlyCmd
          VehSpdLgt
          PostImpctBrkgRdy
          EscCtrlIndcn
          EscSt
          AmbTIndcdWithUnit
          AccrPedlRat
          ReqForPassAirbIndcnAckd
          ActvnStsOfRtrctrRvsbRi
          ActvnStsOfRtrctrRvsbLe
          StsForRtrctrRvsbLe
          BrkSysCylPMst
          AccrpedlSts
          PassAirbLampStsRec
          VehMtnSt
          EngN2
          ThrPos
          PinionSteerAgMax1
          DrvrSeatPosPerc
          PassSeatPosPerc
          DoorDrvrLockSts
          DoorLeReLockSts
          DoorPassLockSts
          DoorRiReLockSts
          PinionSteerAgGroup
          PreCrashFrontData
          PosnBrief
          AbsSts
          BrkAndAbsWarnIndcnReq
          LeFrntTireMsg
          RiFrntTireMsg
          LeReTireMsg
          RiReTireMsg
          StsForRtrctrRvsbRi
          VehBattU
          AsyALgtSts
          CrsCtrlrSts
          DispOfPrpsnModForEv
          DispOfPrpsnMod
          VehTiAndData
          TrsmActrPosnSafe
          Vin
          GearLvrIndcn
          AsyAutDrvCtrlTyp
          DrvrCrsCtrlFctSeld
          CrsCtrlrStbOk
          CrsCtrlrActvnOk
          BrkTracCtrlActv
          EpbSts
          RlyPwrDistbnCmd1WdIgnRlyExtCmd
          EmgyAsscTrigSts
          IsgSpdActSgn
          WhlMotSysSpdAct
          VehHomePrkgSysSts
          SwtIndcr
          SwtLiHzrdWarn
          BrkPedlrRat
          SftyDecelGroupSafe
          Overlap
          VehSpdIndcd
          PrkgStsToEDR
          AsySftyFctStsToEDR
          CllsnMtgtnFctSts
          CllsnAidPost
          CllsnFwdWarn
          SftyAirbRollovrSuppSwt
          SumActv
          EfuseKL15Req{1..5}
          CrsCtrlrMsg
          PassAirbNotiConfirm
          PassStuMonSts
          DrvrStuMonSts
          TurnIndcrAndHwlByDrvInt
          BkpOfDstTrvld
          ZCUDMResdSig1ToSRSSafety
          BrkFricTqTotAtWhlsAct
          EngNSafe
          HoodSts
          BrkTqAtWhlsReq
      SettingsVehicle
        outer-ports:
          RecOfPostImpctBrkgCfmd
          RecOfPostImpctBrkgSuspc
          BrkPedlSts
          CrashSts2
          NotifForEmgyCall
          RestrntSysLampReq
          RestrntSysMsgReq
          BltLockStAtDrvr
          BltLockStAtRowSecLe
          BltLockStAtRowSecMid
          BltLockStAtRowSecRi
          BltLockStAtRowThrdLe
          BltLockStAtRowThrdRi
          BltLockStSafeAtDrvr
          PassAirbLampReq
          RecOfImpct
          PedProtnMsgReqForImpct
          PedProtnMsgReqForFlt
          BltLockStAtPass
          SafetyCrashFb
          CrashStsSafe
          BltLockStAtRowThrdMid
          SeatOccptAtRowThrdMid
          BltLockStAtPassMid
          BltLockStAtRowFrthLe
          BltLockStAtRowFrthMid
          BltLockStAtRowFrthRi
          PassMidSeatSts
          SeatOccptAtRowFrthLe
          SeatOccptAtRowFrthMid
          SeatOccptAtRowFrthRi
          RecOfImpct2
          ReqForHzrdInt
          ActvnReqOfRtrctrRvsbLe
          ActvnReqOfRtrctrRvsbRi
          BltCrashNotif
          PassAirbSts
          SRSResdSig1ToZCUDMSafety
          HVfault
          SRSIntVolt
          ReqForAsyDataStorgFromRestrntSys
          AbsCtrlActv
          BrkPedlPsd
          DoorLeReSts
          DoorDrvrSts
          DoorRiReSts
          DoorPassSts
          VehSpdLgt
          PostImpctBrkgRdy
          EscCtrlIndcn
          EscSt
          AmbTIndcdWithUnit
          AccrPedlRat
          ActvnStsOfRtrctrRvsbRi
          ActvnStsOfRtrctrRvsbLe
          StsForRtrctrRvsbLe
          BrkSysCylPMst
          AccrpedlSts
          VehMtnSt
          EngN2
          ThrPos
          PinionSteerAgMax1
          DrvrSeatPosPerc
          PassSeatPosPerc
          DoorDrvrLockSts
          PinionSteerAgGroup
          PreCrashFrontData
          AbsSts
          BrkAndAbsWarnIndcnReq
          StsForRtrctrRvsbRi
          AsyALgtSts
          CrsCtrlrSts
          DispOfPrpsnModForEv
          DispOfPrpsnMod
          VehTiAndData
          TrsmActrPosnSafe
          Vin
          GearLvrIndcn
          AsyAutDrvCtrlTyp
          CrsCtrlrStbOk
          CrsCtrlrActvnOk
          BrkTracCtrlActv
          EpbSts
          RlyPwrDistbnCmd1WdIgnRlyExtCmd
          EmgyAsscTrigSts
          WhlMotSysSpdAct
          VehHomePrkgSysSts
          SwtIndcr
          BrkPedlrRat
          SftyDecelGroupSafe
          Overlap
          VehSpdIndcd
          PrkgStsToEDR
          AsySftyFctStsToEDR
          CllsnMtgtnFctSts
          CllsnAidPost
          CllsnFwdWarn
          SumActv
          CrsCtrlrMsg
          PassStuMonSts
          DrvrStuMonSts
          TurnIndcrAndHwlByDrvInt
          ZCUDMResdSig1ToSRSSafety
      GlobalShortDuration
        outer-ports:
          CrashSts2
          NotifForEmgyCall
          RestrntSysLampReq
          BltLockStAtDrvr
          BltLockStAtRowSecLe
          BltLockStAtRowSecMid
          BltLockStAtRowSecRi
          BltLockStAtRowThrdLe
          BltLockStAtRowThrdRi
          RecOfImpct
          BltLockStAtPass
          SafetyCrashFb
          CrashStsSafe
          SeatOccptAtRowThrdMid
          PassMidSeatSts
          SeatOccptAtRowFrthLe
          SeatOccptAtRowFrthMid
          SeatOccptAtRowFrthRi
          RecOfImpct2
          ReqForHzrdInt
          SRSResdSig1ToZCUDMSafety
          HVfault
          CarModCrashSaved
          BrkPedlPsd
          RlyPwrDistbnCmd1WdIgnRlyCmd
          VehSpdLgt
          VehMtnSt
          VehBattU
          EpbSts
          RlyPwrDistbnCmd1WdIgnRlyExtCmd
          EmgyAsscTrigSts
          IsgSpdActSgn
          WhlMotSysSpdAct
          BrkPedlrRat
          SumActv
          EfuseKL15Req{1..5}
          TurnIndcrAndHwlByDrvInt
          ZCUDMResdSig1ToSRSSafety
      SeatComfortFunctions
        outer-ports:
          RecOfPostImpctBrkgCfmd
          RecOfPostImpctBrkgSuspc
          BrkPedlSts
          CrashSts2
          NotifForEmgyCall
          RestrntSysLampReq
          RestrntSysMsgReq
          BltLockStAtDrvr
          BltLockStAtRowSecLe
          BltLockStAtRowSecMid
          BltLockStAtRowSecRi
          BltLockStAtRowThrdLe
          BltLockStAtRowThrdRi
          BltLockStSafeAtDrvr
          PassAirbLampReq
          RecOfImpct
          PedProtnMsgReqForImpct
          PedProtnMsgReqForFlt
          BltLockStAtPass
          SafetyCrashFb
          CrashStsSafe
          BltLockStAtRowThrdMid
          SeatOccptAtRowThrdMid
          BltLockStAtPassMid
          BltLockStAtRowFrthLe
          BltLockStAtRowFrthMid
          BltLockStAtRowFrthRi
          PassMidSeatSts
          SeatOccptAtRowFrthLe
          SeatOccptAtRowFrthMid
          SeatOccptAtRowFrthRi
          RecOfImpct2
          BltCrashNotif
          PassAirbSts
          SRSResdSig1ToZCUDMSafety
          RlyPwrDistbnCmd1WdIgnRlyCmd
          AccrPedlRat
          AccrpedlSts
          EngN2
          ThrPos
          DrvrSeatPosPerc
          PassSeatPosPerc
          CrsCtrlrSts
          DispOfPrpsnModForEv
          DispOfPrpsnMod
          GearLvrIndcn
          CrsCtrlrStbOk
          CrsCtrlrActvnOk
          RlyPwrDistbnCmd1WdIgnRlyExtCmd
          EfuseKL15Req{1..5}
          CrsCtrlrMsg
          ZCUDMResdSig1ToSRSSafety
      Crash
        outer-ports:
          RecOfPostImpctBrkgCfmd
          RecOfPostImpctBrkgSuspc
          BrkPedlSts
          CrashSts2
          NotifForEmgyCall
          RestrntSysLampReq
          RestrntSysMsgReq
          BltLockStAtDrvr
          BltLockStAtRowSecLe
          BltLockStAtRowSecMid
          BltLockStAtRowSecRi
          BltLockStAtRowThrdLe
          BltLockStAtRowThrdRi
          BltLockStSafeAtDrvr
          PassAirbLampReq
          RecOfImpct
          PedProtnMsgReqForImpct
          PedProtnMsgReqForFlt
          BltLockStAtPass
          SafetyCrashFb
          CrashStsSafe
          BltLockStAtRowThrdMid
          SeatOccptAtRowThrdMid
          BltLockStAtPassMid
          BltLockStAtRowFrthLe
          BltLockStAtRowFrthMid
          BltLockStAtRowFrthRi
          PassMidSeatSts
          SeatOccptAtRowFrthLe
          SeatOccptAtRowFrthMid
          SeatOccptAtRowFrthRi
          RecOfImpct2
          ReqForHzrdInt
          DstTrvldFromSftyBkp
          DstTrvldVldFromSftyBkp
          ActvnReqOfRtrctrRvsbLe
          ActvnReqOfRtrctrRvsbRi
          BltCrashNotif
          PassAirbSts
          SRSResdSig1ToZCUDMSafety
          HVfault
          SRSIntVolt
          SftyAirbRollovrSuppSts
          PassAirbStsChgNotifReq
          AbsCtrlActv
          CarModCrashSaved
          BrkPedlPsd
          DoorLeReSts
          DoorDrvrSts
          DoorRiReSts
          DoorPassSts
          RlyPwrDistbnCmd1WdIgnRlyCmd
          VehSpdLgt
          PostImpctBrkgRdy
          EscCtrlIndcn
          EscSt
          AmbTIndcdWithUnit
          AccrPedlRat
          ReqForPassAirbIndcnAckd
          ActvnStsOfRtrctrRvsbRi
          ActvnStsOfRtrctrRvsbLe
          StsForRtrctrRvsbLe
          BrkSysCylPMst
          AccrpedlSts
          PassAirbLampStsRec
          VehMtnSt
          EngN2
          ThrPos
          DrvrSeatPosPerc
          PassSeatPosPerc
          DoorDrvrLockSts
          DoorLeReLockSts
          DoorPassLockSts
          DoorRiReLockSts
          PosnBrief
          AbsSts
          BrkAndAbsWarnIndcnReq
          LeFrntTireMsg
          RiFrntTireMsg
          LeReTireMsg
          RiReTireMsg
          StsForRtrctrRvsbRi
          VehBattU
          CrsCtrlrSts
          DispOfPrpsnModForEv
          DispOfPrpsnMod
          VehTiAndData
          TrsmActrPosnSafe
          Vin
          GearLvrIndcn
          DrvrCrsCtrlFctSeld
          CrsCtrlrStbOk
          CrsCtrlrActvnOk
          BrkTracCtrlActv
          EpbSts
          RlyPwrDistbnCmd1WdIgnRlyExtCmd
          EmgyAsscTrigSts
          IsgSpdActSgn
          WhlMotSysSpdAct
          VehHomePrkgSysSts
          SwtLiHzrdWarn
          BrkPedlrRat
          VehSpdIndcd
          PrkgStsToEDR
          SftyAirbRollovrSuppSwt
          EfuseKL15Req{1..5}
          CrsCtrlrMsg
          PassAirbNotiConfirm
          PassStuMonSts
          DrvrStuMonSts
          TurnIndcrAndHwlByDrvInt
          BkpOfDstTrvld
          ZCUDMResdSig1ToSRSSafety
      ParkingDrivingClimatization
        outer-ports:
          RecOfPostImpctBrkgCfmd
          RecOfPostImpctBrkgSuspc
          BrkPedlSts
          CrashSts2
          NotifForEmgyCall
          RestrntSysLampReq
          RestrntSysMsgReq
          BltLockStAtDrvr
          BltLockStAtRowSecLe
          BltLockStAtRowSecMid
          BltLockStAtRowSecRi
          BltLockStAtRowThrdLe
          BltLockStAtRowThrdRi
          BltLockStSafeAtDrvr
          PassAirbLampReq
          RecOfImpct
          PedProtnMsgReqForImpct
          PedProtnMsgReqForFlt
          BltLockStAtPass
          SafetyCrashFb
          CrashStsSafe
          BltLockStAtRowThrdMid
          SeatOccptAtRowThrdMid
          BltLockStAtPassMid
          BltLockStAtRowFrthLe
          BltLockStAtRowFrthMid
          BltLockStAtRowFrthRi
          PassMidSeatSts
          SeatOccptAtRowFrthLe
          SeatOccptAtRowFrthMid
          SeatOccptAtRowFrthRi
          RecOfImpct2
          ReqForHzrdInt
          BltCrashNotif
          PassAirbSts
          SRSResdSig1ToZCUDMSafety
          HVfault
          SftyAirbRollovrSuppSts
          PassAirbStsChgNotifReq
          AbsCtrlActv
          CarModCrashSaved
          BrkPedlPsd
          DoorLeReSts
          DoorDrvrSts
          DoorRiReSts
          DoorPassSts
          RlyPwrDistbnCmd1WdIgnRlyCmd
          VehSpdLgt
          PostImpctBrkgRdy
          EscCtrlIndcn
          EscSt
          AmbTIndcdWithUnit
          AccrPedlRat
          ReqForPassAirbIndcnAckd
          BrkSysCylPMst
          AccrpedlSts
          VehMtnSt
          EngN2
          ThrPos
          DrvrSeatPosPerc
          PassSeatPosPerc
          DoorDrvrLockSts
          DoorLeReLockSts
          DoorPassLockSts
          DoorRiReLockSts
          PosnBrief
          AbsSts
          BrkAndAbsWarnIndcnReq
          LeFrntTireMsg
          RiFrntTireMsg
          LeReTireMsg
          RiReTireMsg
          VehBattU
          CrsCtrlrSts
          DispOfPrpsnModForEv
          DispOfPrpsnMod
          VehTiAndData
          TrsmActrPosnSafe
          Vin
          GearLvrIndcn
          DrvrCrsCtrlFctSeld
          CrsCtrlrStbOk
          CrsCtrlrActvnOk
          BrkTracCtrlActv
          EpbSts
          RlyPwrDistbnCmd1WdIgnRlyExtCmd
          EmgyAsscTrigSts
          IsgSpdActSgn
          WhlMotSysSpdAct
          SwtLiHzrdWarn
          BrkPedlrRat
          VehSpdIndcd
          SftyAirbRollovrSuppSwt
          EfuseKL15Req{1..5}
          CrsCtrlrMsg
          PassAirbNotiConfirm
          PassStuMonSts
          DrvrStuMonSts
          TurnIndcrAndHwlByDrvInt
          ZCUDMResdSig1ToSRSSafety
